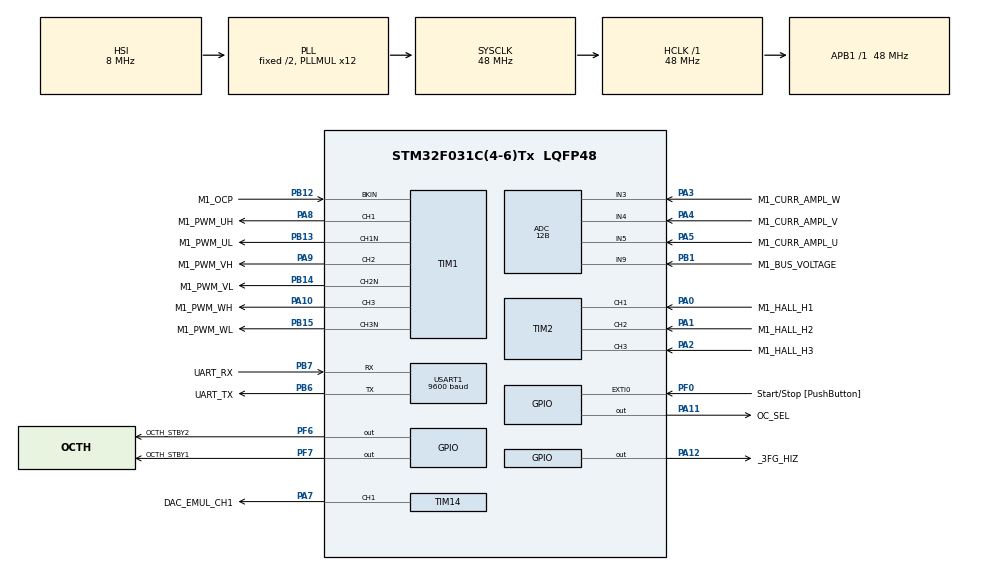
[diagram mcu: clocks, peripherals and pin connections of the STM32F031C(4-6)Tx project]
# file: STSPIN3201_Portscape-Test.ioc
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ADC.ClockPrescaler=ADC_CLOCK_ASYNC_DIV1
ADC.ContinuousConvMode=DISABLE
ADC.DMAContinuousRequests=ENABLE
ADC.DataAlign=ADC_DATAALIGN_LEFT
ADC.DiscontinuousConvMode=DISABLE
ADC.EOCSelection=ADC_EOC_SINGLE_CONV
ADC.EnableAnalogWatchDog=false
ADC.ExternalTrigConv=ADC_EXTERNALTRIGCONV_T1_TRGO
ADC.ExternalTrigConvEdge=ADC_EXTERNALTRIGCONVEDGE_RISING
ADC.LowPowerAutoPowerOff=DISABLE
ADC.LowPowerAutoWait=DISABLE
ADC.Overrun=ADC_OVR_DATA_PRESERVED
ADC.Resolution=ADC_RESOLUTION_12B
ADC.SamplingTime=ADC_SAMPLETIME_28CYCLES_5
ADC.ScanConvMode=ADC_SCAN_DIRECTION_FORWARD
Dma.ADC.0.Direction=DMA_PERIPH_TO_MEMORY
Dma.ADC.0.Instance=DMA1_Channel1
Dma.ADC.0.MemDataAlignment=DMA_MDATAALIGN_HALFWORD
Dma.ADC.0.MemInc=DMA_MINC_ENABLE
Dma.ADC.0.Mode=DMA_CIRCULAR
Dma.ADC.0.PeriphDataAlignment=DMA_PDATAALIGN_HALFWORD
Dma.ADC.0.PeriphInc=DMA_PINC_DISABLE
Dma.ADC.0.Priority=DMA_PRIORITY_HIGH
Dma.Request0=ADC
ExtraMW=MotorControl
ExtraMW.MotorControl.Config=MotorControl
ExtraMW.MotorControl.Mode=MotorControl
ExtraMW.MotorControl.Root=MCSDK_v5.4.8/MotorControl
ExtraMW.MotorControl.Template=templates
Mcu.Family=STM32F0
Mcu.Name=STM32F031C(4-6)Tx
Mcu.Package=LQFP48
MotorControl.ADC_1_PERIPH=ADC1
MotorControl.ADC_2_PERIPH=ADC2
MotorControl.ADC_AHBPERIPH=RCC_AHBPeriph_ADC12
MotorControl.ADC_CLOCK_WB_DIV=1
MotorControl.ADC_CLOCK_WB_FREQ=12
MotorControl.ADC_PERIPH=ADC1
MotorControl.ADC_REFERENCE_VOLTAGE=3.30
MotorControl.ALIGNMENT_ANGLE_DEG=90
MotorControl.ALIGNMENT_DURATION=700
MotorControl.AMPLIFICATION_GAIN=7.70
MotorControl.ANGC={0,0,0,0,0,0,0,0}
MotorControl.BEMF_CONSISTENCY_GAIN=64
MotorControl.BEMF_CONSISTENCY_TOL=64
MotorControl.BKIN1_FILTER=0
MotorControl.BKIN2_FILTER=0
MotorControl.BKIN2_MODE=NONE
MotorControl.BKIN_MODE=EXT_MODE
MotorControl.BOARD=STEVAL-SPIN3201
MotorControl.BRKIN2_GPIO_AF=GPIO_AF_2
MotorControl.BRKIN_GPIO_AF=GPIO_AF_2
MotorControl.BUS_VOLTAGE_READING=true
MotorControl.CCMRAM_ENABLED=false
MotorControl.CLOCK_FREQUENCY=CPU_CLK_48_MHZ
MotorControl.CLOCK_SOURCE=INTERNAL
MotorControl.CONSTANT1_D=23099
MotorControl.CONSTANT1_Q=23099
MotorControl.CONSTANT2_QD=5253
MotorControl.CORD_BEMF_CONSISTENCY_GAIN=64
MotorControl.CORD_BEMF_CONSISTENCY_TOL=64
MotorControl.CORD_F1=8192
MotorControl.CORD_F2=16384
MotorControl.CORD_FIFO_DEPTH_01HZ=64
MotorControl.CORD_FIFO_DEPTH_DPP=64
MotorControl.CORD_GAIN1=-8949
MotorControl.CORD_GAIN2=6439
MotorControl.CORD_MAX_ACCEL_DPPP=44
MotorControl.CORD_MEAS_ERRORS_BEFORE_FAULTS=3
MotorControl.CORD_VARIANCE_THRESHOLD=4
MotorControl.CPU_CLK_48_MHZ=true
MotorControl.CTRBDID=10010
MotorControl.CUBE_MX_VER=6.6.0
MotorControl.CURRENT_READING_TOPOLOGY=THREE_SHUNT
MotorControl.CURR_SAMPLING_TIME=28
MotorControl.DAC_EMULATED=true
MotorControl.DAC_EMULATED_1=CH1
MotorControl.DAC_FUNCTIONALITY=true
MotorControl.DAC_TIMER_CH1_GPIO_PIN=LL_GPIO_PIN_7
MotorControl.DAC_TIMER_CH1_GPIO_PORT=GPIOA
MotorControl.DAC_TIMER_CH2_GPIO_PIN=LL_GPIO_PIN_0
MotorControl.DAC_TIMER_CH2_GPIO_PORT=GPIOA
MotorControl.DAC_TIMER_SELECTION=TIM14
MotorControl.DC_CURRENT_RS_MEAS=4.37
MotorControl.DEBUG_DAC_CH1=true
MotorControl.DEBUG_DAC_CH2=false
MotorControl.DEFAULT_CONTROL_MODE=STC_SPEED_MODE
MotorControl.DEFAULT_DAC_CHANNEL_1=MC_PROTOCOL_REG_I_A
MotorControl.DEFAULT_DAC_CHANNEL_2=MC_PROTOCOL_REG_I_B
MotorControl.DEFAULT_DAC_MOTOR=0
MotorControl.DEFAULT_FLUX_COMPONENT=0
MotorControl.DEFAULT_TARGET_SPEED_RPM=4500
MotorControl.DEFAULT_TORQUE_COMPONENT=0
MotorControl.DISSIPATIVE_BRAKE_POLARITY=DOUT_ACTIVE_HIGH
MotorControl.DRIVES_NUMBER_SELECTION=SINGLEDRIVE
MotorControl.EMERGENCY2_STOP_GPIO_PIN=LL_GPIO_PIN_12
MotorControl.EMERGENCY2_STOP_GPIO_PORT=GPIOB
MotorControl.EMERGENCY_STOP_GPIO_PIN=LL_GPIO_PIN_12
MotorControl.EMERGENCY_STOP_GPIO_PORT=GPIOB
MotorControl.ENABLE_SL_ALGO_FROM_PHASE=3
MotorControl.ENCODER_AVAILABLE=false
MotorControl.ENCODER_PPR=400
MotorControl.ENC_AVERAGING_FIFO_DEPTH=16
MotorControl.ENC_A_GPIO_PIN=LL_GPIO_PIN_0
MotorControl.ENC_A_GPIO_PORT=GPIOA
MotorControl.ENC_B_GPIO_PIN=LL_GPIO_PIN_1
MotorControl.ENC_B_GPIO_PORT=GPIOA
MotorControl.ENC_ICx_FILTER=32
MotorControl.ENC_INVERT_SPEED=false
MotorControl.ENC_MEAS_ERRORS_BEFORE_FAULTS=3
MotorControl.ENC_TIMER_REMAPPING=NO_REMAP_TIM2
MotorControl.ENC_TIMER_SELECTION=ENC_TIM2
MotorControl.ENC_USE_CH3=false
MotorControl.EXT_CLOCK_FREQUENCY=INT_RC_OSC
MotorControl.F1=8192
MotorControl.F2=16384
MotorControl.FEEDBACK_NET_FILTERING=false
MotorControl.FEED_FORWARD_CURRENT_REG_ENABLING=false
MotorControl.FINAL_I_ALIGNMENT=2981
MotorControl.FLUX_WEAKENING_ENABLING=false
MotorControl.FW_KIDIV=32768
MotorControl.FW_KI_GAIN=5000
MotorControl.FW_KPDIV=32768
MotorControl.FW_KP_GAIN=3000
MotorControl.FW_VOLTAGE_REF=985
MotorControl.GAIN1=-8949
MotorControl.GAIN2=6439
MotorControl.H1_GPIO_PIN=LL_GPIO_PIN_0
MotorControl.H1_GPIO_PORT=GPIOA
MotorControl.H2_GPIO_PIN=LL_GPIO_PIN_1
MotorControl.H2_GPIO_PORT=GPIOA
MotorControl.H3_GPIO_PIN=LL_GPIO_PIN_2
MotorControl.H3_GPIO_PORT=GPIOA
MotorControl.HALL_AVERAGING_FIFO_DEPTH=6
MotorControl.HALL_ICx_FILTER=64
MotorControl.HALL_MEAS_ERRORS_BEFORE_FAULTS=3
MotorControl.HALL_MTPA=false
MotorControl.HALL_PHASE_SHIFT=300
MotorControl.HALL_SENSORS=true
MotorControl.HALL_SENSORS_AVAILABLE=true
MotorControl.HALL_SENSORS_PLACEMENT=DEGREES_120
MotorControl.HALL_TIMER_REMAPPING=NO_REMAP_TIM2
MotorControl.HALL_TIMER_SELECTION=HALL_TIM2
MotorControl.HFI_AMPLITUDE=25
MotorControl.HFI_DC_0_COEFF=0.00146
MotorControl.HFI_DC_1_COEFF=0.002921
MotorControl.HFI_DC_2_COEFF=0.00146
MotorControl.HFI_DC_3_COEFF=1.889033
MotorControl.HFI_DC_4_COEFF=-0.894874
MotorControl.HFI_DEBUG_MODE=false
MotorControl.HFI_FREQUENCY=400
MotorControl.HFI_HIFRAMPLSCAN=25
MotorControl.HFI_HP_ID_0_COEFF=0.910377
MotorControl.HFI_HP_ID_1_COEFF=-1.820754
MotorControl.HFI_HP_ID_2_COEFF=0.910377
MotorControl.HFI_HP_ID_3_COEFF=1.812706
MotorControl.HFI_HP_ID_4_COEFF=-0.828803
MotorControl.HFI_IDH_DELAY=32400
MotorControl.HFI_LOCKFREQ=49
MotorControl.HFI_LP_ID_0_COEFF=0.012898
MotorControl.HFI_LP_ID_1_COEFF=0.025796
MotorControl.HFI_LP_ID_2_COEFF=0.012898
MotorControl.HFI_LP_ID_3_COEFF=1.654019
MotorControl.HFI_LP_ID_4_COEFF=-0.705611
MotorControl.HFI_MAXANGLEDIFF=3640
MotorControl.HFI_MINIMUM_SPEED_RPM=402
MotorControl.HFI_NOTCH_IQD_0_COEFF=0.954985
MotorControl.HFI_NOTCH_IQD_1_COEFF=-1.875714
MotorControl.HFI_NOTCH_IQD_2_COEFF=0.954985
MotorControl.HFI_NOTCH_IQD_3_COEFF=1.875714
MotorControl.HFI_NOTCH_IQD_4_COEFF=-0.909971
MotorControl.HFI_NSDETPOINTSSKIP=10
MotorControl.HFI_NSMAXDETPOINTS=20
MotorControl.HFI_NS_MIN_SAT_DIFF=0
MotorControl.HFI_PID_KIDIV=32768
MotorControl.HFI_PID_KI_DEFAULT=400
MotorControl.HFI_PID_KPDIV=16384
MotorControl.HFI_PID_KP_DEFAULT=800
MotorControl.HFI_PLL_KI_DEFAULT=0.00400
MotorControl.HFI_PLL_KP_DEFAULT=0.00060
MotorControl.HFI_RESTARTTIMESEC=0.1
MotorControl.HFI_RESTART_RPM_TH=(((HFI_STO_RPM_TH)+(STO_HFI_RPM_TH))/2)
MotorControl.HFI_REVERT_DIRECTION=true
MotorControl.HFI_SCANROTATIONSNO=3
MotorControl.HFI_SPD_BUFFER_DEPTH_01HZ=64
MotorControl.HFI_STEPANGLE=3640
MotorControl.HFI_STO_RPM_TH=OBS_MINIMUM_SPEED_RPM
MotorControl.HFI_WAITAFTERNS2=4
MotorControl.HFI_WAITBEFORESN=6
MotorControl.HFI_WAITSYNCH=20
MotorControl.HFI_WAITTRACK=20
MotorControl.HIGH_SIDE_BRAKE_STATE=false
MotorControl.HIGH_SIDE_IDLE_STATE=false
MotorControl.HW_COMPLEMENTED_LOW_SIDE=false
MotorControl.HW_DEAD_TIME_NS=100
MotorControl.HW_OV_CURRENT_PROT_BYPASS=false
MotorControl.ID_DEMAG=-6682
MotorControl.INRUSH_CURRLIMIT_AT_POWER_ON=true
MotorControl.INRUSH_CURRLIMIT_CHANGE_AFTER_MS=1000
MotorControl.INRUSH_CURRLIMIT_ENABLING=false
MotorControl.INRUSH_CURRLIMIT_GPIO_PIN=LL_GPIO_PIN_4
MotorControl.INRUSH_CURRLIMIT_GPIO_PORT=GPIOE
MotorControl.INRUSH_CURR_LIMITER_POLARITY=DOUT_ACTIVE_HIGH
MotorControl.INTERNAL_OVERCURRENTPROTECTION=false
MotorControl.INTERNAL_OVERVOLTAGEPROTECTION=false
MotorControl.INT_RC_OSC=true
MotorControl.IPs=NVIC,RCC,SYS,MotorControl,TIM1,ADC,DMA,TIM2,TIM14,USART1
MotorControl.IQMAX=6682
MotorControl.LCD_JOYSTICK_FUNCTIONALITY=false
MotorControl.LCD_MODE=LCD_FULL
MotorControl.LDLQ_RATIO=1.000
MotorControl.LOW_SIDE_BRAKE_STATE=false
MotorControl.LOW_SIDE_IDLE_STATE=false
MotorControl.LOW_SIDE_SIGNALS_ENABLING=LS_PWM_TIMER
MotorControl.LS=0.000050
MotorControl.MAX_APPLICATION_SPEED=49000
MotorControl.MAX_MODULATION_81_PER_CENT=true
MotorControl.MAX_MODULATION_INDEX=MAX_MODULATION_81_PER_CENT
MotorControl.MCU=STSPIN32F0
MotorControl.MCU_TYPE=STSPIN32F0
MotorControl.MC_WORKBENCH_VERSION=5.4.8.21553
MotorControl.MEAS_ERRORS_BEFORE_FAULTS=3
MotorControl.MIN_APPLICATION_SPEED=0
MotorControl.MOTOR_MAX_SPEED_RPM=49000
MotorControl.MOTOR_TYPE=PMSM
MotorControl.MOTOR_VOLTAGE_CONSTANT=0.5
MotorControl.MTPA_ENABLING=false
MotorControl.NB_CONSECUTIVE_TESTS=2
MotorControl.NOMINAL_BUS_VOLTAGE_V=24
MotorControl.NOMINAL_CURRENT=6682
MotorControl.OBS_MEAS_ERRORS_BEFORE_FAULTS=3
MotorControl.OBS_MINIMUM_SPEED_RPM=580
MotorControl.OCPA_INVERTINGINPUT=COMPX_InvertingInput_VREF
MotorControl.OCPA_INVERTINGINPUT_GPIO_PIN=LL_GPIO_PIN_4
MotorControl.OCPA_INVERTINGINPUT_GPIO_PORT=GPIOA
MotorControl.OCPA_INVERTINGINPUT_MODE=INT_MODE
MotorControl.OCPA_NONINVERTINGINPUT=COMP1_NonInvertingInput_PA1
MotorControl.OCPA_NONINVERTINGINPUT_GPIO_PIN=LL_GPIO_PIN_1
MotorControl.OCPA_NONINVERTINGINPUT_GPIO_PORT=GPIOA
MotorControl.OCPA_OUTPUT=COMP_Output_TIM1BKIN2
MotorControl.OCPA_OUTPUTPOL=COMP_OutputPol_NonInverted
MotorControl.OCPA_OUTPUT_GPIO_AF=GPIO_AF_2
MotorControl.OCPA_OUTPUT_GPIO_PIN=LL_GPIO_PIN_0
MotorControl.OCPA_OUTPUT_GPIO_PORT=GPIOA
MotorControl.OCPA_OUTPUT_MODE=INT_MODE
MotorControl.OCPA_SELECTION=COMP1
MotorControl.OCPB_INVERTINGINPUT=COMPX_InvertingInput_VREF
MotorControl.OCPB_INVERTINGINPUT_GPIO_PIN=LL_GPIO_PIN_4
MotorControl.OCPB_INVERTINGINPUT_GPIO_PORT=GPIOA
MotorControl.OCPB_INVERTINGINPUT_MODE=INT_MODE
MotorControl.OCPB_NONINVERTINGINPUT=COMP2_NonInvertingInput_PA7
MotorControl.OCPB_NONINVERTINGINPUT_GPIO_PIN=LL_GPIO_PIN_7
MotorControl.OCPB_NONINVERTINGINPUT_GPIO_PORT=GPIOA
MotorControl.OCPB_OUTPUT=COMP_Output_TIM1BKIN2
MotorControl.OCPB_OUTPUTPOL=COMP_OutputPol_NonInverted
MotorControl.OCPB_OUTPUT_GPIO_AF=GPIO_AF_2
MotorControl.OCPB_OUTPUT_GPIO_PIN=LL_GPIO_PIN_2
MotorControl.OCPB_OUTPUT_GPIO_PORT=GPIOA
MotorControl.OCPB_OUTPUT_MODE=INT_MODE
MotorControl.OCPB_SELECTION=COMP2
MotorControl.OCPC_INVERTINGINPUT=COMPX_InvertingInput_VREF
MotorControl.OCPC_INVERTINGINPUT_GPIO_PIN=LL_GPIO_PIN_4
MotorControl.OCPC_INVERTINGINPUT_GPIO_PORT=GPIOA
MotorControl.OCPC_INVERTINGINPUT_MODE=INT_MODE
MotorControl.OCPC_NONINVERTINGINPUT=COMP3_NonInvertingInput_PB14
MotorControl.OCPC_NONINVERTINGINPUT_GPIO_PIN=LL_GPIO_PIN_14
MotorControl.OCPC_NONINVERTINGINPUT_GPIO_PORT=GPIOB
MotorControl.OCPC_OUTPUT=COMP_Output_TIM1BKIN2
MotorControl.OCPC_OUTPUTPOL=COMP_OutputPol_NonInverted
MotorControl.OCPC_OUTPUT_GPIO_AF=GPIO_AF_2
MotorControl.OCPC_OUTPUT_GPIO_PIN=LL_GPIO_PIN_8
MotorControl.OCPC_OUTPUT_GPIO_PORT=GPIOC
MotorControl.OCPC_OUTPUT_MODE=INT_MODE
MotorControl.OCPC_SELECTION=COMP3
MotorControl.OCPREF=23830
MotorControl.OCP_COMP_THRESHOLD=0.50
MotorControl.OCP_FILTER=COMP_Mode_HighSpeed
MotorControl.OCP_INVERTINGINPUT=COMPX_InvertingInput_VREF
MotorControl.OCP_INVERTINGINPUT_GPIO_PIN=LL_GPIO_PIN_4
MotorControl.OCP_INVERTINGINPUT_GPIO_PORT=GPIOA
MotorControl.OCP_INVERTINGINPUT_MODE=INT_MODE
MotorControl.OCP_NONINVERTINGINPUT=COMP2_NonInvertingInput_PA7
MotorControl.OCP_NONINVERTINGINPUT_GPIO_PIN=LL_GPIO_PIN_7
MotorControl.OCP_NONINVERTINGINPUT_GPIO_PORT=GPIOA
MotorControl.OCP_OUTPUT=COMP_Output_TIM1BKIN2
MotorControl.OCP_OUTPUTPOL=COMP_OutputPol_NonInverted
MotorControl.OCP_OUTPUT_GPIO_AF=GPIO_AF_2
MotorControl.OCP_OUTPUT_GPIO_PIN=LL_GPIO_PIN_2
MotorControl.OCP_OUTPUT_GPIO_PORT=GPIOA
MotorControl.OCP_OUTPUT_MODE=INT_MODE
MotorControl.OCP_SELECTION=COMP2
MotorControl.OFST={0,0,0,0,0,0,0,0}
MotorControl.ON_OVER_VOLTAGE=TURN_OFF_PWM
MotorControl.OPAMP1_INVERTINGINPUT=OPAMP1_InvertingInput_PGA
MotorControl.OPAMP1_INVERTINGINPUT_GPIO_PIN=LL_GPIO_PIN_3
MotorControl.OPAMP1_INVERTINGINPUT_GPIO_PORT=GPIOA
MotorControl.OPAMP1_INVERTINGINPUT_MODE=INT_MODE
MotorControl.OPAMP1_NONINVERTINGINPUT_PHA=OPAMP1_NonInvertingInput_PA1
MotorControl.OPAMP1_NONINVERTINGINPUT_PHA_GPIO_PIN=LL_GPIO_PIN_1
MotorControl.OPAMP1_NONINVERTINGINPUT_PHA_GPIO_PORT=GPIOA
MotorControl.OPAMP1_NONINVERTINGINPUT_PHB=OPAMP1_NonInvertingInput_PA7
MotorControl.OPAMP1_NONINVERTINGINPUT_PHB_GPIO_PIN=LL_GPIO_PIN_7
MotorControl.OPAMP1_NONINVERTINGINPUT_PHB_GPIO_PORT=GPIOA
MotorControl.OPAMP1_OUT_GPIO_PIN=LL_GPIO_PIN_2
MotorControl.OPAMP1_OUT_GPIO_PORT=GPIOA
MotorControl.OPAMP1_SELECTION=OPAMP1
MotorControl.OPAMP2_INVERTINGINPUT=OPAMP2_InvertingInput_PGA
MotorControl.OPAMP2_INVERTINGINPUT_GPIO_PIN=LL_GPIO_PIN_5
MotorControl.OPAMP2_INVERTINGINPUT_GPIO_PORT=GPIOC
MotorControl.OPAMP2_INVERTINGINPUT_MODE=INT_MODE
MotorControl.OPAMP2_NONINVERTINGINPUT_PHA=OPAMP2_NonInvertingInput_PB14
MotorControl.OPAMP2_NONINVERTINGINPUT_PHA_GPIO_PIN=LL_GPIO_PIN_14
MotorControl.OPAMP2_NONINVERTINGINPUT_PHA_GPIO_PORT=GPIOB
MotorControl.OPAMP2_NONINVERTINGINPUT_PHB=OPAMP2_NonInvertingInput_PA7
MotorControl.OPAMP2_NONINVERTINGINPUT_PHB_GPIO_PIN=LL_GPIO_PIN_7
MotorControl.OPAMP2_NONINVERTINGINPUT_PHB_GPIO_PORT=GPIOA
MotorControl.OPAMP2_NONINVERTINGINPUT_PHC=OPAMP2_NonInvertingInput_PB14
MotorControl.OPAMP2_NONINVERTINGINPUT_PHC_GPIO_PIN=LL_GPIO_PIN_14
MotorControl.OPAMP2_NONINVERTINGINPUT_PHC_GPIO_PORT=GPIOB
MotorControl.OPAMP2_OUT_GPIO_PIN=LL_GPIO_PIN_6
MotorControl.OPAMP2_OUT_GPIO_PORT=GPIOA
MotorControl.OPAMP2_SELECTION=OPAMP2
MotorControl.OPAMP3_INVERTINGINPUT=OPAMP1_InvertingInput_PGA
MotorControl.OPAMP3_INVERTINGINPUT_GPIO_PIN=LL_GPIO_PIN_0
MotorControl.OPAMP3_INVERTINGINPUT_GPIO_PORT=GPIOA
MotorControl.OPAMP3_INVERTINGINPUT_MODE=INT_MODE
MotorControl.OPAMP3_SELECTION=OPAMP1
MotorControl.OPAMP_INVERTINGINPUT=OPAMP1_InvertingInput_PGA
MotorControl.OPAMP_INVERTINGINPUT_GPIO_PIN=LL_GPIO_PIN_3
MotorControl.OPAMP_INVERTINGINPUT_GPIO_PORT=GPIOA
MotorControl.OPAMP_INVERTINGINPUT_MODE=INT_MODE
MotorControl.OPAMP_NONINVERTINGINPUT=OPAMP1_NonInvertingInput_PA7
MotorControl.OPAMP_NONINVERTINGINPUT_GPIO_PIN=LL_GPIO_PIN_7
MotorControl.OPAMP_NONINVERTINGINPUT_GPIO_PORT=GPIOA
MotorControl.OPAMP_OUT_GPIO_PIN=LL_GPIO_PIN_2
MotorControl.OPAMP_OUT_GPIO_PORT=GPIOA
MotorControl.OPAMP_PGACONNECT=OPAMP_PGAConnect_No
MotorControl.OPAMP_PGAGAIN=OPAMP_OPAMP_PGAGain_2
MotorControl.OPAMP_SELECTION=OPAMP1
MotorControl.OPAMP_TYPE_GAIN=INTERNAL
MotorControl.OPEN_LOOP_FOC=false
MotorControl.OPEN_LOOP_K=44
MotorControl.OPEN_LOOP_OFF=4400
MotorControl.OPEN_LOOP_SPEED_RAMP_DURATION_MS=1000
MotorControl.OPEN_LOOP_SPEED_RPM=100
MotorControl.OPEN_LOOP_VF=false
MotorControl.OPEN_LOOP_VOLTAGE_d=6000
MotorControl.OVERCURR_FEEDBACK_POLARITY=EMSTOP_ACTIVE_HIGH
MotorControl.OVERCURR_PROTECTION_HW_DISABLING=DOUT_ACTIVE_HIGH
MotorControl.OVPREF=23830
MotorControl.OVP_FILTER=COMP_Mode_HighSpeed
MotorControl.OVP_INVERTINGINPUT=COMPX_InvertingInput_VREF
MotorControl.OVP_INVERTINGINPUT_GPIO_PIN=LL_GPIO_PIN_4
MotorControl.OVP_INVERTINGINPUT_GPIO_PORT=GPIOA
MotorControl.OVP_INVERTINGINPUT_MODE=INT_MODE
MotorControl.OVP_NONINVERTINGINPUT=COMP7_NonInvertingInput_PA0
MotorControl.OVP_NONINVERTINGINPUT_GPIO_PIN=LL_GPIO_PIN_0
MotorControl.OVP_NONINVERTINGINPUT_GPIO_PORT=GPIOA
MotorControl.OVP_OUTPUT=COMP_Output_TIM1BKIN
MotorControl.OVP_OUTPUTPOL=COMP_OutputPol_NonInverted
MotorControl.OVP_OUTPUT_GPIO_AF=GPIO_AF_2
MotorControl.OVP_OUTPUT_GPIO_PIN=LL_GPIO_PIN_2
MotorControl.OVP_OUTPUT_GPIO_PORT=GPIOC
MotorControl.OVP_OUTPUT_MODE=INT_MODE
MotorControl.OVP_SELECTION=COMP7
MotorControl.OV_CURR_BYPASS_GPIO_PIN=LL_GPIO_PIN_5
MotorControl.OV_CURR_BYPASS_GPIO_PORT=GPIOE
MotorControl.OV_TEMPERATURE_HYSTERESIS_C=10
MotorControl.OV_TEMPERATURE_PROT_ENABLING=false
MotorControl.OV_TEMPERATURE_THRESHOLD_C=70
MotorControl.OV_VOLTAGE_PROT_ENABLING=true
MotorControl.OV_VOLTAGE_THRESHOLD_V=45
MotorControl.PHASE1_DURATION=0
MotorControl.PHASE1_FINAL_CURRENT=0
MotorControl.PHASE1_FINAL_SPEED_RPM=0
MotorControl.PHASE2_DURATION=700
MotorControl.PHASE2_FINAL_CURRENT=917
MotorControl.PHASE2_FINAL_SPEED_RPM=0
MotorControl.PHASE3_DURATION=350
MotorControl.PHASE3_FINAL_CURRENT=1070
MotorControl.PHASE3_FINAL_SPEED_RPM=630
MotorControl.PHASE4_DURATION=1150
MotorControl.PHASE4_FINAL_CURRENT=1070
MotorControl.PHASE4_FINAL_SPEED_RPM=2700
MotorControl.PHASE5_DURATION=0
MotorControl.PHASE5_FINAL_CURRENT=1070
MotorControl.PHASE5_FINAL_SPEED_RPM=2700
MotorControl.PHASE_CURRENTS_ADC=ADC1_2
MotorControl.PHASE_CURRENTS_CHANNEL=ADC_CHANNEL_9
MotorControl.PHASE_CURRENTS_GPIO_PIN=LL_GPIO_PIN_0
MotorControl.PHASE_CURRENTS_GPIO_PORT=GPIOA
MotorControl.PHASE_UH_GPIO_AF=GPIO_AF_2
MotorControl.PHASE_UH_GPIO_PIN=LL_GPIO_PIN_8
MotorControl.PHASE_UH_GPIO_PORT=GPIOA
MotorControl.PHASE_UH_POLARITY=H_ACTIVE_HIGH
MotorControl.PHASE_UL_GPIO_AF=GPIO_AF_2
MotorControl.PHASE_UL_GPIO_PIN=LL_GPIO_PIN_13
MotorControl.PHASE_UL_GPIO_PORT=GPIOB
MotorControl.PHASE_UL_POLARITY=L_ACTIVE_HIGH
MotorControl.PHASE_U_CURR_ADC=ADC1
MotorControl.PHASE_U_CURR_CHANNEL=ADC_CHANNEL_5
MotorControl.PHASE_U_GPIO_PIN=LL_GPIO_PIN_5
MotorControl.PHASE_U_GPIO_PORT=GPIOA
MotorControl.PHASE_VH_GPIO_AF=GPIO_AF_2
MotorControl.PHASE_VH_GPIO_PIN=LL_GPIO_PIN_9
MotorControl.PHASE_VH_GPIO_PORT=GPIOA
MotorControl.PHASE_VH_POLARITY=H_ACTIVE_HIGH
MotorControl.PHASE_VL_GPIO_AF=GPIO_AF_2
MotorControl.PHASE_VL_GPIO_PIN=LL_GPIO_PIN_14
MotorControl.PHASE_VL_GPIO_PORT=GPIOB
MotorControl.PHASE_VL_POLARITY=L_ACTIVE_HIGH
MotorControl.PHASE_V_CURR_ADC=ADC1
MotorControl.PHASE_V_CURR_CHANNEL=ADC_CHANNEL_4
MotorControl.PHASE_V_GPIO_PIN=LL_GPIO_PIN_4
MotorControl.PHASE_V_GPIO_PORT=GPIOA
MotorControl.PHASE_WH_GPIO_AF=GPIO_AF_2
MotorControl.PHASE_WH_GPIO_PIN=LL_GPIO_PIN_10
MotorControl.PHASE_WH_GPIO_PORT=GPIOA
MotorControl.PHASE_WH_POLARITY=H_ACTIVE_HIGH
MotorControl.PHASE_WL_GPIO_AF=GPIO_AF_2
MotorControl.PHASE_WL_GPIO_PIN=LL_GPIO_PIN_15
MotorControl.PHASE_WL_GPIO_PORT=GPIOB
MotorControl.PHASE_WL_POLARITY=L_ACTIVE_HIGH
MotorControl.PHASE_W_CURR_ADC=ADC1
MotorControl.PHASE_W_CURR_CHANNEL=ADC_CHANNEL_3
MotorControl.PHASE_W_GPIO_PIN=LL_GPIO_PIN_3
MotorControl.PHASE_W_GPIO_PORT=GPIOA
MotorControl.PID_FLUX_KD_DEFAULT=100
MotorControl.PID_FLUX_KI_DEFAULT=3577
MotorControl.PID_FLUX_KP_DEFAULT=3291
MotorControl.PID_SPEED_KD_DEFAULT=0
MotorControl.PID_SPEED_KI_DEFAULT=126
MotorControl.PID_SPEED_KP_DEFAULT=2044
MotorControl.PID_TORQUE_KD_DEFAULT=100
MotorControl.PID_TORQUE_KI_DEFAULT=3577
MotorControl.PID_TORQUE_KP_DEFAULT=3291
MotorControl.PLL_KI_GAIN=210
MotorControl.PLL_KP_GAIN=3935
MotorControl.POLE_PAIR_NUM=2
MotorControl.POSITION_CTRL_ENABLING=false
MotorControl.PWBDID=10010
MotorControl.PWM_FREQUENCY=26500
MotorControl.PWM_TIMER_REMAPPING=PWM_NO_REMAP
MotorControl.PWM_TIMER_SELECTION=PWM_TIM1
MotorControl.REGCONVADC=ADC1
MotorControl.REGULATION_EXECUTION_RATE=2
MotorControl.RS=0.36
MotorControl.RSHUNT=0.01000
MotorControl.RTOS=NONE
MotorControl.R_BRAKE_GPIO_PIN=LL_GPIO_PIN_5
MotorControl.R_BRAKE_GPIO_PORT=GPIOE
MotorControl.R_BRAKE_SWITCH_OFF_THRES_V=36
MotorControl.SEGDIV=0
MotorControl.SERIAL_COMMUNICATION=true
MotorControl.SERIAL_COM_CHANNEL1=MC_PROTOCOL_REG_I_A
MotorControl.SERIAL_COM_CHANNEL2=MC_PROTOCOL_REG_I_A
MotorControl.SERIAL_COM_MODE=COM_BIDIRECTIONAL
MotorControl.SERIAL_COM_MOTOR=0
MotorControl.SHARED_SIGNAL_ENABLE=false
MotorControl.SINGLEDRIVE=true
MotorControl.SPD_DIFFERENTIAL_TERM_ENABLING=false
MotorControl.SPEED_BAND_LOWER_LIMIT=15
MotorControl.SPEED_BAND_UPPER_LIMIT=17
MotorControl.SPEED_LOOP_FREQUENCY_HZ=1000
MotorControl.SPEED_SENSOR_SELECTION=HALL_SENSORS
MotorControl.SP_KDDIV=16
MotorControl.SP_KIDIV=16384
MotorControl.SP_KPDIV=1024
MotorControl.STARTING_ANGLE_DEG=90
MotorControl.START_STOP_BTN=true
MotorControl.START_STOP_GPIO_PIN=LL_GPIO_PIN_0
MotorControl.START_STOP_GPIO_PORT=GPIOF
MotorControl.START_STOP_POLARITY=DIN_ACTIVE_LOW
MotorControl.START_STOP_POLARITY_EDGE=GPIO_PULLUP
MotorControl.STO_FIFO_DEPTH_01HZ=64
MotorControl.STO_FIFO_DEPTH_DPP=64
MotorControl.STO_HFI_RPM_TH=460
MotorControl.STSPIN32F0=true
MotorControl.SW_DEADTIME_NS=800
MotorControl.SW_OV_CURRENT_PROT_ENABLING=true
MotorControl.T0_C=25
MotorControl.TEMPERATURE_READING=false
MotorControl.TEMP_ADC_SAMPLING_TIME=1
MotorControl.TEMP_FDBK_ADC=ADC1
MotorControl.TEMP_FDBK_CHANNEL=ADC_CHANNEL_5
MotorControl.TEMP_FDBK_GPIO_PIN=LL_GPIO_PIN_5
MotorControl.TEMP_FDBK_GPIO_PORT=GPIOA
MotorControl.TFDIFFERENTIAL_TERM_ENABLING=false
MotorControl.TF_KDDIV=8192
MotorControl.TF_KIDIV=8192
MotorControl.TF_KPDIV=4096
MotorControl.THREE_SHUNT=true
MotorControl.TNOISE_NS=1200
MotorControl.TRANSITION_DURATION=0
MotorControl.TRISE_NS=1200
MotorControl.T_MAX=70
MotorControl.UD_VOLTAGE_THRESHOLD_V=8
MotorControl.USART_REMAPPING=NO_REMAP_USART1
MotorControl.USART_RX_GPIO_PIN=LL_GPIO_PIN_7
MotorControl.USART_RX_GPIO_PORT=GPIOB
MotorControl.USART_SELECTION=USE_USART1
MotorControl.USART_SPEED=9600
MotorControl.USART_TX_GPIO_PIN=LL_GPIO_PIN_6
MotorControl.USART_TX_GPIO_PORT=GPIOB
MotorControl.USE_3OPAMPS=false
MotorControl.USE_INTERNAL_OPAMP=false
MotorControl.UV_VOLTAGE_PROT_ENABLING=true
MotorControl.V0_V=0.290
MotorControl.VARIANCE_THRESHOLD=0.1
MotorControl.VBUS_ADC=ADC1
MotorControl.VBUS_ADC_SAMPLING_TIME=28
MotorControl.VBUS_CHANNEL=ADC_CHANNEL_9
MotorControl.VBUS_GPIO_PIN=LL_GPIO_PIN_1
MotorControl.VBUS_GPIO_PORT=GPIOB
MotorControl.VBUS_PARTITIONING_FACTOR=0.0522
MotorControl.WB_to_Mx_template_version=21-11-15
MotorControl.WB_to_Mx_version=1.5.1
MotorControl.dV_dT=0.025
NVIC.DMA1_Channel1_IRQn=true\:1\:0\:true\:true\:false\:3\:true\:true\:true
NVIC.EXTI0_1_IRQn=true\:3\:0\:false\:true\:false\:6\:true\:true\:true
NVIC.TIM1_BRK_UP_TRG_COM_IRQn=true\:0\:0\:false\:true\:false\:1\:true\:true\:true
NVIC.TIM2_IRQn=true\:3\:0\:false\:true\:false\:4\:true\:true\:true
NVIC.USART1_IRQn=true\:3\:0\:true\:true\:false\:5\:true\:true\:true
PA0.GPIO_Label=M1_HALL_H1
PA0.GPIO_Speed=GPIO_SPEED_FREQ_HIGH
PA0.Signal=S_TIM2_CH1_ETR
PA1.GPIO_Label=M1_HALL_H2
PA1.GPIO_Speed=GPIO_SPEED_FREQ_HIGH
PA1.Signal=S_TIM2_CH2
PA10.GPIO_Label=M1_PWM_WH
PA10.GPIO_PuPd=GPIO_PULLDOWN
PA10.GPIO_Speed=GPIO_SPEED_FREQ_HIGH
PA10.Signal=S_TIM1_CH3
PA11.GPIO_Label=OC_SEL
PA11.GPIO_PuPd=GPIO_PULLDOWN
PA11.PinState=GPIO_PIN_SET
PA11.Signal=GPIO_Output
PA12.GPIO_Label=_3FG_HIZ
PA12.GPIO_PuPd=GPIO_PULLDOWN
PA12.Signal=GPIO_Output
PA2.GPIO_Label=M1_HALL_H3
PA2.GPIO_Speed=GPIO_SPEED_FREQ_HIGH
PA2.Signal=S_TIM2_CH3
PA3.GPIO_Label=M1_CURR_AMPL_W
PA3.Mode=IN3
PA3.Signal=ADC_IN3
PA4.GPIO_Label=M1_CURR_AMPL_V
PA4.Mode=IN4
PA4.Signal=ADC_IN4
PA5.GPIO_Label=M1_CURR_AMPL_U
PA5.Mode=IN5
PA5.Signal=ADC_IN5
PA7.GPIO_Label=DAC_EMUL_CH1
PA7.Signal=S_TIM14_CH1
PA8.GPIO_Label=M1_PWM_UH
PA8.GPIO_PuPd=GPIO_PULLDOWN
PA8.GPIO_Speed=GPIO_SPEED_FREQ_HIGH
PA8.Signal=S_TIM1_CH1
PA9.GPIO_Label=M1_PWM_VH
PA9.GPIO_PuPd=GPIO_PULLDOWN
PA9.GPIO_Speed=GPIO_SPEED_FREQ_HIGH
PA9.Signal=S_TIM1_CH2
PB1.GPIO_Label=M1_BUS_VOLTAGE
PB1.Mode=IN9
PB1.Signal=ADC_IN9
PB12.GPIO_Label=M1_OCP
PB12.GPIO_PuPd=GPIO_PULLDOWN
PB12.Mode=Activate-Break-Input
PB12.Signal=TIM1_BKIN
PB13.GPIO_Label=M1_PWM_UL
PB13.GPIO_PuPd=GPIO_PULLDOWN
PB13.GPIO_Speed=GPIO_SPEED_FREQ_HIGH
PB13.Mode=PWM Generation1 CH1 CH1N
PB13.Signal=TIM1_CH1N
PB14.GPIO_Label=M1_PWM_VL
PB14.GPIO_PuPd=GPIO_PULLDOWN
PB14.GPIO_Speed=GPIO_SPEED_FREQ_HIGH
PB14.Mode=PWM Generation2 CH2 CH2N
PB14.Signal=TIM1_CH2N
PB15.GPIO_Label=M1_PWM_WL
PB15.GPIO_PuPd=GPIO_PULLDOWN
PB15.GPIO_Speed=GPIO_SPEED_FREQ_HIGH
PB15.Mode=PWM Generation3 CH3 CH3N
PB15.Signal=TIM1_CH3N
PB6.GPIO_Label=UART_TX
PB6.GPIO_Mode=GPIO_MODE_AF_PP
PB6.GPIO_PuPd=GPIO_NOPULL
PB6.GPIO_Speed=GPIO_SPEED_FREQ_LOW
PB6.Mode=Asynchronous
PB6.Signal=USART1_TX
PB7.GPIO_Label=UART_RX
PB7.GPIO_Mode=GPIO_MODE_AF_PP
PB7.GPIO_PuPd=GPIO_NOPULL
PB7.GPIO_Speed=GPIO_SPEED_FREQ_LOW
PB7.Mode=Asynchronous
PB7.Signal=USART1_RX
PF0-OSC_IN.GPIO_Label=Start/Stop [PushButton]
PF0-OSC_IN.GPIO_ModeDefaultEXTI=GPIO_MODE_IT_FALLING
PF0-OSC_IN.GPIO_PuPd=GPIO_PULLUP
PF0-OSC_IN.Signal=GPXTI0
PF6.GPIO_Label=OCTH_STBY2
PF6.GPIO_PuPd=GPIO_PULLDOWN
PF6.PinState=GPIO_PIN_SET
PF6.Signal=GPIO_Output
PF7.GPIO_Label=OCTH_STBY1
PF7.GPIO_PuPd=GPIO_PULLDOWN
PF7.PinState=GPIO_PIN_SET
PF7.Signal=GPIO_Output
ProjectManager.HeapSize=0x80
ProjectManager.StackSize=0x400
ProjectManager.TargetToolchain=STM32CubeIDE
RCC.AHBFreq_Value=48000000
RCC.APB1Freq_Value=48000000
RCC.APB1TimFreq_Value=48000000
RCC.EnbaleCSS=true
RCC.HCLKFreq_Value=48000000
RCC.PLLMUL=RCC_PLL_MUL12
RCC.SYSCLKFreq_VALUE=48000000
RCC.SYSCLKSource=RCC_SYSCLKSOURCE_PLLCLK
SH.S_TIM14_CH1.0=TIM14_CH1,PWM Generation1 CH1
SH.S_TIM1_CH1.0=TIM1_CH1,PWM Generation1 CH1 CH1N
SH.S_TIM1_CH2.0=TIM1_CH2,PWM Generation2 CH2 CH2N
SH.S_TIM1_CH3.0=TIM1_CH3,PWM Generation3 CH3 CH3N
SH.S_TIM2_CH1_ETR.0=TIM2_CH1,Xored_Inputs_Hall_Sensor_Interface
SH.S_TIM2_CH2.0=TIM2_CH2,Xored_Inputs_Hall_Sensor_Interface
SH.S_TIM2_CH3.0=TIM2_CH3,Xored_Inputs_Hall_Sensor_Interface
TIM1.AutoReloadPreload=TIM_AUTORELOAD_PRELOAD_DISABLE
TIM1.AutomaticOutput=TIM_AUTOMATICOUTPUT_DISABLE
TIM1.BreakPolarity=TIM_BREAKPOLARITY_HIGH
TIM1.BreakState=TIM_BREAK_ENABLE
TIM1.Channel-PWM\ Generation1\ CH1\ CH1N=TIM_CHANNEL_1
TIM1.Channel-PWM\ Generation2\ CH2\ CH2N=TIM_CHANNEL_2
TIM1.Channel-PWM\ Generation3\ CH3\ CH3N=TIM_CHANNEL_3
TIM1.Channel-PWM\ Generation4\ No\ Output=TIM_CHANNEL_4
TIM1.ClockDivision=TIM_CLOCKDIVISION_DIV2
TIM1.CounterMode=TIM_COUNTERMODE_CENTERALIGNED1
TIM1.DeadTime=((DEAD_TIME_COUNTS) / 2)
TIM1.LockLevel=TIM_LOCKLEVEL_1
TIM1.OCIdleState_1=TIM_OCIDLESTATE_RESET
TIM1.OCIdleState_2=TIM_OCIDLESTATE_RESET
TIM1.OCIdleState_3=TIM_OCIDLESTATE_RESET
TIM1.OCIdleState_4=TIM_OCIDLESTATE_RESET
TIM1.OCMode_PWM-PWM\ Generation1\ CH1\ CH1N=TIM_OCMODE_PWM1
TIM1.OCMode_PWM-PWM\ Generation2\ CH2\ CH2N=TIM_OCMODE_PWM1
TIM1.OCMode_PWM-PWM\ Generation3\ CH3\ CH3N=TIM_OCMODE_PWM1
TIM1.OCMode_PWM-PWM\ Generation4\ No\ Output=TIM_OCMODE_PWM2
TIM1.OCNIdleState_1=TIM_OCNIDLESTATE_RESET
TIM1.OCNIdleState_2=TIM_OCNIDLESTATE_RESET
TIM1.OCNIdleState_3=TIM_OCNIDLESTATE_RESET
TIM1.OCNPolarity_1=TIM_OCNPOLARITY_HIGH
TIM1.OCNPolarity_2=TIM_OCNPOLARITY_HIGH
TIM1.OCNPolarity_3=TIM_OCNPOLARITY_HIGH
TIM1.OCPolarity_1=TIM_OCPOLARITY_HIGH
TIM1.OCPolarity_2=TIM_OCPOLARITY_HIGH
TIM1.OCPolarity_3=TIM_OCPOLARITY_HIGH
TIM1.OCPolarity_4=TIM_OCPOLARITY_HIGH
TIM1.OffStateIDLEMode=TIM_OSSI_ENABLE
TIM1.OffStateRunMode=TIM_OSSR_ENABLE
TIM1.Period=((PWM_PERIOD_CYCLES) / 2)
TIM1.Prescaler=((TIM_CLOCK_DIVIDER) - 1)
TIM1.Pulse-PWM\ Generation1\ CH1=((PWM_PERIOD_CYCLES) / 4)
TIM1.Pulse-PWM\ Generation2\ CH2=((PWM_PERIOD_CYCLES) / 4)
TIM1.Pulse-PWM\ Generation3\ CH3=((PWM_PERIOD_CYCLES) / 4)
TIM1.Pulse-PWM\ Generation4\ No\ Output=(((PWM_PERIOD_CYCLES) / 2) - (HTMIN))
TIM1.RepetitionCounter=(REP_COUNTER)
TIM1.TIM_MasterOutputTrigger=TIM_TRGO_OC4REF
TIM1.TIM_MasterSlaveMode=TIM_MASTERSLAVEMODE_DISABLE
TIM14.AutoReloadPreload=TIM_AUTORELOAD_PRELOAD_DISABLE
TIM14.Channel=TIM_CHANNEL_1
TIM14.ClockDivision=TIM_CLOCKDIVISION_DIV1
TIM14.CounterMode=TIM_COUNTERMODE_UP
TIM14.Period=0x800
TIM14.Prescaler=0
TIM14.Pulse=0x400
TIM2.IC1Filter=M1_HALL_IC_FILTER
TIM2.Period=M1_HALL_TIM_PERIOD
USART1.BaudRate=9600
USART1.VirtualMode-Asynchronous=VM_ASYNC
USART1.WordLength=WORDLENGTH_8B
VP_MotorControl_MC_ENABLED.Mode=Enabled
VP_TIM14_VS_ClockSourceINT.Mode=Enable_Timer
VP_TIM1_VS_no_output4.Mode=PWM Generation4 No Output
VP_TIM2_VS_ClockSourceINT.Mode=Internal
board=custom

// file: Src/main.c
/* USER CODE BEGIN Header */
/**
  ******************************************************************************
  * @file           : main.c
  * @brief          : Main program body
  ******************************************************************************
  * @attention
  *
  * Copyright (c) 2022 STMicroelectronics.
  * All rights reserved.
  *
  * This software is licensed under terms that can be found in the LICENSE file
  * in the root directory of this software component.
  * If no LICENSE file comes with this software, it is provided AS-IS.
  *
  ******************************************************************************
  */
/* USER CODE END Header */
#include "main.h"

ADC_HandleTypeDef hadc;
DMA_HandleTypeDef hdma_adc;

TIM_HandleTypeDef htim1;
TIM_HandleTypeDef htim2;
TIM_HandleTypeDef htim14;

UART_HandleTypeDef huart1;

void SystemClock_Config(void);
static void MX_GPIO_Init(void);
static void MX_DMA_Init(void);
static void MX_ADC_Init(void);
static void MX_TIM1_Init(void);
static void MX_TIM2_Init(void);
static void MX_TIM14_Init(void);
static void MX_USART1_UART_Init(void);
static void MX_NVIC_Init(void);
/*-- My code --*/
void Home_Offset(void);
void Mode_Home(void);
void Mode_Home2(void);
void Mode_Home3(void);
void Home_Null_Offset(void);

void OSC_MODE_HOME(void);
void OSC_MODE_HOME2(void);
void MainWhile_Homing(void);
/*-- My code ends --*/

/* USER CODE BEGIN 0 */
/*-- My code --*/
   bool stepA=1,stepB=0,stepC=0,stepCA=0,stepAB=0,stepBC=0,pendingPhase=1, moveMotor =1;
   uint16_t oldhallstate =0, presenthallstate=0,count =0,oldAngle=0,execute = 0,waitToMoveCounter =0;
   int16_t pulse = 100;
   uint8_t MotorHallState = 0;
   uint8_t buffer[20];
//   uint8_t homingOffset = 0;

   uint16_t Null_Offset = 0;
/*-- My code ends --*/
#define STATE_0 (uint8_t)0
#define STATE_1 (uint8_t)1
#define STATE_2 (uint8_t)2
#define STATE_3 (uint8_t)3
#define STATE_4 (uint8_t)4
#define STATE_5 (uint8_t)5
#define STATE_6 (uint8_t)6
#define STATE_7 (uint8_t)7
/* USER CODE END 0 */

int main(void)
{

  /* MCU Configuration--------------------------------------------------------*/

  /* Reset of all peripherals, Initializes the Flash interface and the Systick. */
  HAL_Init();

  /* Configure the system clock */
  SystemClock_Config();

  /* Initialize all configured peripherals */
  MX_GPIO_Init();
  MX_DMA_Init();
  MX_ADC_Init();
  MX_TIM1_Init();
  MX_TIM2_Init();
  MX_TIM14_Init();
  MX_USART1_UART_Init();
  MX_MotorControl_Init();

    /* Initialize interrupts */
    MX_NVIC_Init();
    /* USER CODE BEGIN 2 */

    __HAL_TIM_SET_COMPARE(&htim1,TIM_CHANNEL_1,0);
    __HAL_TIM_SET_COMPARE(&htim1,TIM_CHANNEL_2,0);
    __HAL_TIM_SET_COMPARE(&htim1,TIM_CHANNEL_3,0);
    HAL_TIM_PWM_Start(&htim1,TIM_CHANNEL_1);
    HAL_TIM_PWM_Start(&htim1,TIM_CHANNEL_2);
    HAL_TIM_PWM_Start(&htim1,TIM_CHANNEL_3);

    /* USER CODE END 2 */
    //MotorHallState = HALL_M1.HallStateCounter;
   // HAL_UART_Transmit(&huart1, (uint8_t*)buffer, sprintf(buffer, "\t STATE: %u\r\n", HALL_M1.HallStateCounter), 100);
    /* Infinite loop */
    /* USER CODE BEGIN WHILE */
    while (1)
    {
//    	HAL_UART_Transmit(&huart1, (uint8_t*)buffer, sprintf(buffer, "\t CASE 6, HallState:  %u\r\n", HALL_M1.HallState), 100);
//    	HAL_UART_Transmit(&huart1, (uint8_t*)buffer, sprintf(buffer, "\t CASE 6, HallStateCounter:  %u\r\n", HALL_M1.HallStateCounter), 100);
//    	HAL_UART_Transmit(&huart1, (uint8_t*)buffer, sprintf(buffer, "\t CASE 6, HallStateHomePosition:  %u\r\n", HALL_M1.HallStateHomePosition), 100);
//    	HAL_UART_Transmit(&huart1, (uint8_t*)buffer, sprintf(buffer, "\t CASE 6, HallCounterHomePosition:  %u\r\n", HALL_M1.HallCounterHomePosition), 100);
    	HAL_UART_Transmit(&huart1, (uint8_t*)buffer, sprintf(buffer, "\t CASE 6, HallCounterHomePosition:  %u\r\n", Null_Offset), 100);
    	HAL_Delay(1000);
    /* USER CODE BEGIN 3 */
  }
  /* USER CODE END 3 */
}

void Mode_Home(){

	uint8_t HallState_Internal = HALL_M1.HallState;
	uint8_t HallStateCounter_Internal = (HALL_M1.HallStateCounter + (Null_Offset%72));
	uint8_t HallState_Home = HALL_M1.HallStateHomePosition;
	uint8_t HallStateCounter_Home = HALL_M1.HallCounterHomePosition;

//	HAL_UART_Transmit(&huart1, (uint8_t*)buffer, sprintf(buffer, "\t Input:  %u\r\n", HallState_Internal), 100);
	while (HallStateCounter_Internal != HallStateCounter_Home){ //&&(HallState_Home != HallState_Home)
		switch(HallState_Internal){
		//step 1
				case STATE_6:
					  __HAL_TIM_SET_COMPARE(&htim1,TIM_CHANNEL_1,pulse);
					  __HAL_TIM_SET_COMPARE(&htim1,TIM_CHANNEL_2,0);
					  __HAL_TIM_SET_COMPARE(&htim1,TIM_CHANNEL_3,0);
					  HallState_Internal++;
					  HallStateCounter_Internal++;
					  HAL_UART_Transmit(&huart1, (uint8_t*)buffer, sprintf(buffer, "\t CASE 6, HallState:  %u\r\n", HallState_Internal), 100);
//					  HAL_UART_Transmit(&huart1, (uint8_t*)buffer, sprintf(buffer, "\t CASE 5, HallCounter:  %u\r\n", HallStateCounter_Internal), 100);
//					  HAL_UART_Transmit(&huart1, (uint8_t*)buffer, sprintf(buffer, "\t CASE 5, HallStateCounter_Home:  %u\r\n", HallStateCounter_Home), 100);
					break;
				//step 2
				case STATE_1:
				  	  __HAL_TIM_SET_COMPARE(&htim1,TIM_CHANNEL_1,pulse);
				  	  __HAL_TIM_SET_COMPARE(&htim1,TIM_CHANNEL_2,pulse);
				  	  __HAL_TIM_SET_COMPARE(&htim1,TIM_CHANNEL_3,0);
					  HallState_Internal++;
					  HallStateCounter_Internal++;
					  HAL_UART_Transmit(&huart1, (uint8_t*)buffer, sprintf(buffer, "\t CASE 1, HallState:  %u\r\n", HallState_Internal), 100);
//					  HAL_UART_Transmit(&huart1, (uint8_t*)buffer, sprintf(buffer, "\t CASE 3, HallCounter:  %u\r\n", HallStateCounter_Internal), 100);
//					  HAL_UART_Transmit(&huart1, (uint8_t*)buffer, sprintf(buffer, "\t CASE 5, HallStateCounter_Home:  %u\r\n", HallStateCounter_Home), 100);
					break;
				//step 3
				case STATE_2:
					  __HAL_TIM_SET_COMPARE(&htim1,TIM_CHANNEL_1,0);
					  __HAL_TIM_SET_COMPARE(&htim1,TIM_CHANNEL_2,pulse);
					  __HAL_TIM_SET_COMPARE(&htim1,TIM_CHANNEL_3,0);
					  HallState_Internal++;
					  HallStateCounter_Internal++;
					  HAL_UART_Transmit(&huart1, (uint8_t*)buffer, sprintf(buffer, "\t CASE 2, HallState:  %u\r\n", HallState_Internal), 100);
//					  HAL_UART_Transmit(&huart1, (uint8_t*)buffer, sprintf(buffer, "\t CASE 1, HallCounter:  %u\r\n", HallStateCounter_Internal), 100);
//					  HAL_UART_Transmit(&huart1, (uint8_t*)buffer, sprintf(buffer, "\t CASE 5, HallStateCounter_Home:  %u\r\n", HallStateCounter_Home), 100);
					break;
				//step 4
				case STATE_3:
				  	    __HAL_TIM_SET_COMPARE(&htim1,TIM_CHANNEL_1,0);
				  	    __HAL_TIM_SET_COMPARE(&htim1,TIM_CHANNEL_2,pulse);
				  	    __HAL_TIM_SET_COMPARE(&htim1,TIM_CHANNEL_3,pulse);
						  HallState_Internal++;
						  HallStateCounter_Internal++;
						  HAL_UART_Transmit(&huart1, (uint8_t*)buffer, sprintf(buffer, "\t CASE 3, HallState:  %u\r\n", HallState_Internal), 100);
//						  HAL_UART_Transmit(&huart1, (uint8_t*)buffer, sprintf(buffer, "\t CASE 6, HallCounter:  %u\r\n", HallStateCounter_Internal), 100);
//						  HAL_UART_Transmit(&huart1, (uint8_t*)buffer, sprintf(buffer, "\t CASE 5, HallStateCounter_Home:  %u\r\n", HallStateCounter_Home), 100);
					break;
				//step 5
				case STATE_4:
					__HAL_TIM_SET_COMPARE(&htim1,TIM_CHANNEL_1,0);
					__HAL_TIM_SET_COMPARE(&htim1,TIM_CHANNEL_2,0);
					__HAL_TIM_SET_COMPARE(&htim1,TIM_CHANNEL_3,pulse);
					  HallState_Internal++;
					  HallStateCounter_Internal++;
					  HAL_UART_Transmit(&huart1, (uint8_t*)buffer, sprintf(buffer, "\t CASE 4, HallState:  %u\r\n", HallState_Internal), 100);
//					  HAL_UART_Transmit(&huart1, (uint8_t*)buffer, sprintf(buffer, "\t CASE 4, HallCounter:  %u\r\n", HallStateCounter_Internal), 100);
//					  HAL_UART_Transmit(&huart1, (uint8_t*)buffer, sprintf(buffer, "\t CASE 5, HallStateCounter_Home:  %u\r\n", HallStateCounter_Home), 100);
					break;
				//step 6
				case STATE_5:
					 __HAL_TIM_SET_COMPARE(&htim1,TIM_CHANNEL_1,pulse);
					 __HAL_TIM_SET_COMPARE(&htim1,TIM_CHANNEL_2,0);
					 __HAL_TIM_SET_COMPARE(&htim1,TIM_CHANNEL_3,pulse);
					  HallState_Internal++;
					  HallStateCounter_Internal++;
					  HAL_UART_Transmit(&huart1, (uint8_t*)buffer, sprintf(buffer, "\t CASE 5, HallState:  %u\r\n", HallState_Internal), 100);
//					  HAL_UART_Transmit(&huart1, (uint8_t*)buffer, sprintf(buffer, "\t CASE 2, HallCounter:  %u\r\n", HallStateCounter_Internal), 100);
//					  HAL_UART_Transmit(&huart1, (uint8_t*)buffer, sprintf(buffer, "\t CASE 5, HallStateCounter_Home:  %u\r\n", HallStateCounter_Home), 100);
					break;
				default:
					HAL_UART_Transmit(&huart1, (uint8_t*)buffer, sprintf(buffer, "\t Error, HallState:  %u\r\n", HallState_Internal), 100);
//					HAL_UART_Transmit(&huart1, (uint8_t*)buffer, sprintf(buffer, "\t Error, HallCounter:  %u\r\n", HallStateCounter_Internal), 100);
//					HAL_UART_Transmit(&huart1, (uint8_t*)buffer, sprintf(buffer, "\t CASE 5, HallStateCounter_Home:  %u\r\n", HallStateCounter_Home), 100);
					break;
		}

		HallStateCounter_Internal = HallStateCounter_Internal%72;

		if(HallState_Internal ==7)
		{
			HallState_Internal =1;
		}

	}
	  __HAL_TIM_SET_COMPARE(&htim1,TIM_CHANNEL_1,0);
	  __HAL_TIM_SET_COMPARE(&htim1,TIM_CHANNEL_2,0);
	  __HAL_TIM_SET_COMPARE(&htim1,TIM_CHANNEL_3,0);
	  //NOte this two lines
//	  HALL_M1.HallStateCounter = 0;
	  HALL_M1.HallStateCounter = HALL_M1.HallCounterHomePosition;
	  HALL_M1.HallStateHomePosition = HALL_M1.HallState;
	  Null_Offset = 0;
}

//void Home_Offset(){
//	HAL_UART_Transmit(&huart1, (uint8_t*)buffer, sprintf(buffer, "---------------------------------------\n"), 100);
//	HAL_UART_Transmit(&huart1, (uint8_t*)buffer, sprintf(buffer, "\t Prev STATE COunter: %u\r\n", HALL_M1.HallCounterHomePosition), 100);
//	HAL_UART_Transmit(&huart1, (uint8_t*)buffer, sprintf(buffer, "\t PRev Hall POSITION: %u\r\n", HALL_M1.HallStateHomePosition), 100);
//	HALL_M1.HallCounterHomePosition = HALL_M1.HallStateCounter +1;
////	homingOffset = HALL_M1.HallStateCounter +1;
////	homingOffset +=1;
////	homingOffset = homingOffset%72;
//	//HALL_M1.HallStateHomePosition = HALL_M1.HallState;
//	HAL_UART_Transmit(&huart1, (uint8_t*)buffer, sprintf(buffer, "\t New STATE COunter: %u\r\n", HALL_M1.HallCounterHomePosition), 100);
//	HAL_UART_Transmit(&huart1, (uint8_t*)buffer, sprintf(buffer, "\t New Hall POSITION: %u\r\n", HALL_M1.HallStateHomePosition), 100);
//	Mode_Home2();
////	HALL_M1.HallStateCounter = HALL_M1.HallCounterHomePosition;
//	HAL_UART_Transmit(&huart1, (uint8_t*)buffer, sprintf(buffer, "---------------------------------------\n"), 100);
//}

void Home_Offset(){
	// 21 01 10 34
//	HAL_UART_Transmit(&huart1, (uint8_t*)buffer, sprintf(buffer, "\t Prev HALL homrCOunter: %u\r\n", HALL_M1.HallCounterHomePosition), 100);
//	HAL_UART_Transmit(&huart1, (uint8_t*)buffer, sprintf(buffer, "\t PRev Hall State home POSITION: %u\r\n", HALL_M1.HallStateHomePosition), 100);
	HALL_M1.HallCounterHomePosition = HALL_M1.HallCounterHomePosition +1;
//	HALL_M1.HallStateHomePosition = HALL_M1.HallState;
//	HAL_UART_Transmit(&huart1, (uint8_t*)buffer, sprintf(buffer, "\t New HAll home COunter: %u\r\n", HALL_M1.HallCounterHomePosition), 100);
//	HAL_UART_Transmit(&huart1, (uint8_t*)buffer, sprintf(buffer, "\t New Hall home State POSITION: %u\r\n", HALL_M1.HallStateHomePosition), 100);
	Mode_Home3();
//	HAL_UART_Transmit(&huart1, (uint8_t*)buffer, sprintf(buffer, "\t Final HAll Home COunter: %u\r\n", HALL_M1.HallCounterHomePosition), 100);
//	HAL_UART_Transmit(&huart1, (uint8_t*)buffer, sprintf(buffer, "\t Final Hall state home POSITION: %u\r\n", HALL_M1.HallStateHomePosition), 100);
//	HAL_UART_Transmit(&huart1, (uint8_t*)buffer, sprintf(buffer, "\t Final hall COunter: %u\r\n", HALL_M1.HallStateCounter), 100);
//	HAL_UART_Transmit(&huart1, (uint8_t*)buffer, sprintf(buffer, "\t Final Hall POSITION: %u\r\n", HALL_M1.HallState), 100);
}
void Mode_Home3(){

	uint8_t HallState_Internal = HALL_M1.HallState;
	uint8_t HallStateCounter_Internal = HALL_M1.HallStateCounter;
	uint8_t HallState_Home = HALL_M1.HallStateHomePosition;
	uint8_t HallStateCounter_Home = HALL_M1.HallCounterHomePosition;

	HAL_UART_Transmit(&huart1, (uint8_t*)buffer, sprintf(buffer, "\t Input:  %u\r\n", HallState_Internal), 100);
//	while (HallStateCounter_Internal != HallStateCounter_Home){ //&&(HallState_Home != HallState_Home)
		switch(HallState_Internal){
		//step 1
				case STATE_6:
					  __HAL_TIM_SET_COMPARE(&htim1,TIM_CHANNEL_1,0);
					  __HAL_TIM_SET_COMPARE(&htim1,TIM_CHANNEL_2,pulse);
					  __HAL_TIM_SET_COMPARE(&htim1,TIM_CHANNEL_3,pulse);
					  HallState_Internal++;
					  HallStateCounter_Internal++;
					  HAL_UART_Transmit(&huart1, (uint8_t*)buffer, sprintf(buffer, "\t CASE 6, HallState:  %u\r\n", HallState_Internal), 100);
//					  HAL_UART_Transmit(&huart1, (uint8_t*)buffer, sprintf(buffer, "\t CASE 5, HallCounter:  %u\r\n", HallStateCounter_Internal), 100);
//					  HAL_UART_Transmit(&huart1, (uint8_t*)buffer, sprintf(buffer, "\t CASE 5, HallStateCounter_Home:  %u\r\n", HallStateCounter_Home), 100);
					break;
				//step 2
				case STATE_1:
				  	  __HAL_TIM_SET_COMPARE(&htim1,TIM_CHANNEL_1,0);
				  	  __HAL_TIM_SET_COMPARE(&htim1,TIM_CHANNEL_2,0);
				  	  __HAL_TIM_SET_COMPARE(&htim1,TIM_CHANNEL_3,pulse);
					  HallState_Internal++;
					  HallStateCounter_Internal++;
					  HAL_UART_Transmit(&huart1, (uint8_t*)buffer, sprintf(buffer, "\t CASE 1, HallState:  %u\r\n", HallState_Internal), 100);
//					  HAL_UART_Transmit(&huart1, (uint8_t*)buffer, sprintf(buffer, "\t CASE 3, HallCounter:  %u\r\n", HallStateCounter_Internal), 100);
//					  HAL_UART_Transmit(&huart1, (uint8_t*)buffer, sprintf(buffer, "\t CASE 5, HallStateCounter_Home:  %u\r\n", HallStateCounter_Home), 100);
					break;
				//step 3
				case STATE_2:
					  __HAL_TIM_SET_COMPARE(&htim1,TIM_CHANNEL_1,pulse);
					  __HAL_TIM_SET_COMPARE(&htim1,TIM_CHANNEL_2,0);
					  __HAL_TIM_SET_COMPARE(&htim1,TIM_CHANNEL_3,pulse);
					  HallState_Internal++;
					  HallStateCounter_Internal++;
					  HAL_UART_Transmit(&huart1, (uint8_t*)buffer, sprintf(buffer, "\t CASE 2, HallState:  %u\r\n", HallState_Internal), 100);
//					  HAL_UART_Transmit(&huart1, (uint8_t*)buffer, sprintf(buffer, "\t CASE 1, HallCounter:  %u\r\n", HallStateCounter_Internal), 100);
//					  HAL_UART_Transmit(&huart1, (uint8_t*)buffer, sprintf(buffer, "\t CASE 5, HallStateCounter_Home:  %u\r\n", HallStateCounter_Home), 100);
					break;
				//step 4
				case STATE_3:
				  	    __HAL_TIM_SET_COMPARE(&htim1,TIM_CHANNEL_1,pulse);
				  	    __HAL_TIM_SET_COMPARE(&htim1,TIM_CHANNEL_2,0);
				  	    __HAL_TIM_SET_COMPARE(&htim1,TIM_CHANNEL_3,0);
						  HallState_Internal++;
						  HallStateCounter_Internal++;
						  HAL_UART_Transmit(&huart1, (uint8_t*)buffer, sprintf(buffer, "\t CASE 3, HallState:  %u\r\n", HallState_Internal), 100);
//						  HAL_UART_Transmit(&huart1, (uint8_t*)buffer, sprintf(buffer, "\t CASE 6, HallCounter:  %u\r\n", HallStateCounter_Internal), 100);
//						  HAL_UART_Transmit(&huart1, (uint8_t*)buffer, sprintf(buffer, "\t CASE 5, HallStateCounter_Home:  %u\r\n", HallStateCounter_Home), 100);
					break;
				//step 5
				case STATE_4:
					__HAL_TIM_SET_COMPARE(&htim1,TIM_CHANNEL_1,pulse);
					__HAL_TIM_SET_COMPARE(&htim1,TIM_CHANNEL_2,pulse);
					__HAL_TIM_SET_COMPARE(&htim1,TIM_CHANNEL_3,0);
					  HallState_Internal++;
					  HallStateCounter_Internal++;
					  HAL_UART_Transmit(&huart1, (uint8_t*)buffer, sprintf(buffer, "\t CASE 4, HallState:  %u\r\n", HallState_Internal), 100);
//					  HAL_UART_Transmit(&huart1, (uint8_t*)buffer, sprintf(buffer, "\t CASE 4, HallCounter:  %u\r\n", HallStateCounter_Internal), 100);
//					  HAL_UART_Transmit(&huart1, (uint8_t*)buffer, sprintf(buffer, "\t CASE 5, HallStateCounter_Home:  %u\r\n", HallStateCounter_Home), 100);
					break;
				//step 6
				case STATE_5:
					 __HAL_TIM_SET_COMPARE(&htim1,TIM_CHANNEL_1,0);
					 __HAL_TIM_SET_COMPARE(&htim1,TIM_CHANNEL_2,pulse);
					 __HAL_TIM_SET_COMPARE(&htim1,TIM_CHANNEL_3,0);
					  HallState_Internal++;
					  HallStateCounter_Internal++;
					  HAL_UART_Transmit(&huart1, (uint8_t*)buffer, sprintf(buffer, "\t CASE 5, HallState:  %u\r\n", HallState_Internal), 100);
//					  HAL_UART_Transmit(&huart1, (uint8_t*)buffer, sprintf(buffer, "\t CASE 2, HallCounter:  %u\r\n", HallStateCounter_Internal), 100);
//					  HAL_UART_Transmit(&huart1, (uint8_t*)buffer, sprintf(buffer, "\t CASE 5, HallStateCounter_Home:  %u\r\n", HallStateCounter_Home), 100);
					break;
				default:
					HAL_UART_Transmit(&huart1, (uint8_t*)buffer, sprintf(buffer, "\t Error, HallState:  %u\r\n", HallState_Internal), 100);
//					HAL_UART_Transmit(&huart1, (uint8_t*)buffer, sprintf(buffer, "\t Error, HallCounter:  %u\r\n", HallStateCounter_Internal), 100);
//					HAL_UART_Transmit(&huart1, (uint8_t*)buffer, sprintf(buffer, "\t CASE 5, HallStateCounter_Home:  %u\r\n", HallStateCounter_Home), 100);
					break;
		}

		HallStateCounter_Internal = HallStateCounter_Internal%72;

		if(HallState_Internal ==7)
		{
			HallState_Internal =1;
		}

//	}
	  __HAL_TIM_SET_COMPARE(&htim1,TIM_CHANNEL_1,0);
	  __HAL_TIM_SET_COMPARE(&htim1,TIM_CHANNEL_2,0);
	  __HAL_TIM_SET_COMPARE(&htim1,TIM_CHANNEL_3,0);
	  //NOte this two lines
//	  HALL_M1.HallStateCounter = 0;
	  HALL_M1.HallStateCounter = HALL_M1.HallCounterHomePosition;
	  HALL_M1.HallStateHomePosition = HALL_M1.HallState;
}
void Mode_Home2(){
	uint8_t HallState_Internal = HALL_M1.HallState;
	uint8_t HallStateCounter_Internal = HALL_M1.HallStateCounter;
	uint8_t HallState_Home = HALL_M1.HallStateHomePosition;
	uint8_t HallStateCounter_Home = HALL_M1.HallCounterHomePosition;// + homingOffset;

	while (HallStateCounter_Internal != HallStateCounter_Home){ //&&(HallState_Home != HallState_Home)
		switch(HallState_Internal){
			   //step 1
			   case STATE_6://STATE_2:
					  __HAL_TIM_SET_COMPARE(&htim1,TIM_CHANNEL_1,0);
					  __HAL_TIM_SET_COMPARE(&htim1,TIM_CHANNEL_2,pulse);
					  __HAL_TIM_SET_COMPARE(&htim1,TIM_CHANNEL_3,0);
					  HallState_Internal++;
					  HallStateCounter_Internal++;
					  HAL_UART_Transmit(&huart1, (uint8_t*)buffer, sprintf(buffer, "\t CASE 6, HallState:  %u\r\n", HallState_Internal), 100);
//					  HAL_UART_Transmit(&huart1, (uint8_t*)buffer, sprintf(buffer, "\t CASE 5, HallCounter:  %u\r\n", HallStateCounter_Internal), 100);
//					  HAL_UART_Transmit(&huart1, (uint8_t*)buffer, sprintf(buffer, "\t CASE 5, HallStateCounter_Home:  %u\r\n", HallStateCounter_Home), 100);
//				      for(int i =0; i<5000;i++);
					break;
				//step 2
				case STATE_1://STATE_3:
				  	  __HAL_TIM_SET_COMPARE(&htim1,TIM_CHANNEL_1,pulse);
				  	  __HAL_TIM_SET_COMPARE(&htim1,TIM_CHANNEL_2,0);
				  	  __HAL_TIM_SET_COMPARE(&htim1,TIM_CHANNEL_3,0);
					  HallState_Internal++;
					  HallStateCounter_Internal++;
					  HAL_UART_Transmit(&huart1, (uint8_t*)buffer, sprintf(buffer, "\t CASE 1, HallState:  %u\r\n", HallState_Internal), 100);
//					  HAL_UART_Transmit(&huart1, (uint8_t*)buffer, sprintf(buffer, "\t CASE 3, HallCounter:  %u\r\n", HallStateCounter_Internal), 100);
//					  HAL_UART_Transmit(&huart1, (uint8_t*)buffer, sprintf(buffer, "\t CASE 5, HallStateCounter_Home:  %u\r\n", HallStateCounter_Home), 100);
//				      for(int i =0; i<5000;i++);
					break;
				//step 3
				case STATE_2://STATE_4:
					  __HAL_TIM_SET_COMPARE(&htim1,TIM_CHANNEL_1,pulse);
					  __HAL_TIM_SET_COMPARE(&htim1,TIM_CHANNEL_2,pulse);
					  __HAL_TIM_SET_COMPARE(&htim1,TIM_CHANNEL_3,0);
					  HallState_Internal++;
					  HallStateCounter_Internal++;
					  HAL_UART_Transmit(&huart1, (uint8_t*)buffer, sprintf(buffer, "\t CASE 2, HallState:  %u\r\n", HallState_Internal), 100);
//					  HAL_UART_Transmit(&huart1, (uint8_t*)buffer, sprintf(buffer, "\t CASE 1, HallCounter:  %u\r\n", HallStateCounter_Internal), 100);
//					  HAL_UART_Transmit(&huart1, (uint8_t*)buffer, sprintf(buffer, "\t CASE 5, HallStateCounter_Home:  %u\r\n", HallStateCounter_Home), 100);
//				      for(int i =0; i<5000;i++);
					break;
				//step 4
				case STATE_3://STATE_5:
				  	    __HAL_TIM_SET_COMPARE(&htim1,TIM_CHANNEL_1,0);
				  	    __HAL_TIM_SET_COMPARE(&htim1,TIM_CHANNEL_2,pulse);
				  	    __HAL_TIM_SET_COMPARE(&htim1,TIM_CHANNEL_3,pulse);
						  HallState_Internal++;
						  HallStateCounter_Internal++;
						  HAL_UART_Transmit(&huart1, (uint8_t*)buffer, sprintf(buffer, "\t CASE 3, HallState:  %u\r\n", HallState_Internal), 100);
//						  HAL_UART_Transmit(&huart1, (uint8_t*)buffer, sprintf(buffer, "\t CASE 6, HallCounter:  %u\r\n", HallStateCounter_Internal), 100);
//						  HAL_UART_Transmit(&huart1, (uint8_t*)buffer, sprintf(buffer, "\t CASE 5, HallStateCounter_Home:  %u\r\n", HallStateCounter_Home), 100);
//					      for(int i =0; i<5000;i++);
					break;
				//step 5
				case STATE_4://STATE_6:
					__HAL_TIM_SET_COMPARE(&htim1,TIM_CHANNEL_1,0);
					__HAL_TIM_SET_COMPARE(&htim1,TIM_CHANNEL_2,0);
					__HAL_TIM_SET_COMPARE(&htim1,TIM_CHANNEL_3,pulse);
					  HallState_Internal++;
					  HallStateCounter_Internal++;
					  HAL_UART_Transmit(&huart1, (uint8_t*)buffer, sprintf(buffer, "\t CASE 4, HallState:  %u\r\n", HallState_Internal), 100);
//					  HAL_UART_Transmit(&huart1, (uint8_t*)buffer, sprintf(buffer, "\t CASE 4, HallCounter:  %u\r\n", HallStateCounter_Internal), 100);
//					  HAL_UART_Transmit(&huart1, (uint8_t*)buffer, sprintf(buffer, "\t CASE 5, HallStateCounter_Home:  %u\r\n", HallStateCounter_Home), 100);
//				      for(int i =0; i<5000;i++);
					break;
				//step 6
				case STATE_5://STATE_1:
					 __HAL_TIM_SET_COMPARE(&htim1,TIM_CHANNEL_1,pulse);
					 __HAL_TIM_SET_COMPARE(&htim1,TIM_CHANNEL_2,0);
					 __HAL_TIM_SET_COMPARE(&htim1,TIM_CHANNEL_3,pulse);
					  HallState_Internal++;
					  HallStateCounter_Internal++;
					  HAL_UART_Transmit(&huart1, (uint8_t*)buffer, sprintf(buffer, "\t CASE 5, HallState:  %u\r\n", HallState_Internal), 100);
//					  HAL_UART_Transmit(&huart1, (uint8_t*)buffer, sprintf(buffer, "\t CASE 2, HallCounter:  %u\r\n", HallStateCounter_Internal), 100);
//					  HAL_UART_Transmit(&huart1, (uint8_t*)buffer, sprintf(buffer, "\t CASE 5, HallStateCounter_Home:  %u\r\n", HallStateCounter_Home), 100);
//				      for(int i =0; i<5000;i++);
					break;
				default:
					HAL_UART_Transmit(&huart1, (uint8_t*)buffer, sprintf(buffer, "\t Error, HallState:  %u\r\n", HallState_Internal), 100);
//					HAL_UART_Transmit(&huart1, (uint8_t*)buffer, sprintf(buffer, "\t Error, HallCounter:  %u\r\n", HallStateCounter_Internal), 100);
//					HAL_UART_Transmit(&huart1, (uint8_t*)buffer, sprintf(buffer, "\t CASE 5, HallStateCounter_Home:  %u\r\n", HallStateCounter_Home), 100);
//					for(int i =0; i<5000;i++);
					break;
		}

		HallStateCounter_Internal = HallStateCounter_Internal%72;
		if(HallState_Internal ==7)
		{
			HallState_Internal =1;
		}

	}
	  __HAL_TIM_SET_COMPARE(&htim1,TIM_CHANNEL_1,0);
	  __HAL_TIM_SET_COMPARE(&htim1,TIM_CHANNEL_2,0);
	  __HAL_TIM_SET_COMPARE(&htim1,TIM_CHANNEL_3,0);
	  HALL_M1.HallStateCounter = HALL_M1.HallCounterHomePosition;
	  HALL_M1.HallStateHomePosition = HALL_M1.HallState;
}

void Home_Null_Offset(){
//	Null_Offset = 0;
	Null_Offset = Null_Offset + HALL_M1.HallStateCounter;
}

/**
  * @brief System Clock Configuration
  * @retval None
  */
void SystemClock_Config(void)
{
  RCC_OscInitTypeDef RCC_OscInitStruct = {0};
  RCC_ClkInitTypeDef RCC_ClkInitStruct = {0};
  RCC_PeriphCLKInitTypeDef PeriphClkInit = {0};

  /** Initializes the RCC Oscillators according to the specified parameters
  * in the RCC_OscInitTypeDef structure.
  */
  RCC_OscInitStruct.OscillatorType = RCC_OSCILLATORTYPE_HSI|RCC_OSCILLATORTYPE_HSI14;
  RCC_OscInitStruct.HSIState = RCC_HSI_ON;
  RCC_OscInitStruct.HSI14State = RCC_HSI14_ON;
  RCC_OscInitStruct.HSICalibrationValue = RCC_HSICALIBRATION_DEFAULT;
  RCC_OscInitStruct.HSI14CalibrationValue = 16;
  RCC_OscInitStruct.PLL.PLLState = RCC_PLL_ON;
  RCC_OscInitStruct.PLL.PLLSource = RCC_PLLSOURCE_HSI;
  RCC_OscInitStruct.PLL.PLLMUL = RCC_PLL_MUL12;
  RCC_OscInitStruct.PLL.PREDIV = RCC_PREDIV_DIV1;
  if (HAL_RCC_OscConfig(&RCC_OscInitStruct) != HAL_OK)
  {
    Error_Handler();
  }

  /** Initializes the CPU, AHB and APB buses clocks
  */
  RCC_ClkInitStruct.ClockType = RCC_CLOCKTYPE_HCLK|RCC_CLOCKTYPE_SYSCLK
                              |RCC_CLOCKTYPE_PCLK1;
  RCC_ClkInitStruct.SYSCLKSource = RCC_SYSCLKSOURCE_PLLCLK;
  RCC_ClkInitStruct.AHBCLKDivider = RCC_SYSCLK_DIV1;
  RCC_ClkInitStruct.APB1CLKDivider = RCC_HCLK_DIV1;

  if (HAL_RCC_ClockConfig(&RCC_ClkInitStruct, FLASH_LATENCY_1) != HAL_OK)
  {
    Error_Handler();
  }
  PeriphClkInit.PeriphClockSelection = RCC_PERIPHCLK_USART1;
  PeriphClkInit.Usart1ClockSelection = RCC_USART1CLKSOURCE_PCLK1;
  if (HAL_RCCEx_PeriphCLKConfig(&PeriphClkInit) != HAL_OK)
  {
    Error_Handler();
  }

  /** Enables the Clock Security System
  */
  HAL_RCC_EnableCSS();
}

/**
  * @brief NVIC Configuration.
  * @retval None
  */
static void MX_NVIC_Init(void)
{
  /* TIM1_BRK_UP_TRG_COM_IRQn interrupt configuration */
  HAL_NVIC_SetPriority(TIM1_BRK_UP_TRG_COM_IRQn, 0, 0);
  HAL_NVIC_EnableIRQ(TIM1_BRK_UP_TRG_COM_IRQn);
  /* DMA1_Channel1_IRQn interrupt configuration */
  HAL_NVIC_SetPriority(DMA1_Channel1_IRQn, 1, 0);
  HAL_NVIC_EnableIRQ(DMA1_Channel1_IRQn);
  /* TIM2_IRQn interrupt configuration */
  HAL_NVIC_SetPriority(TIM2_IRQn, 3, 0);
  HAL_NVIC_EnableIRQ(TIM2_IRQn);
  /* USART1_IRQn interrupt configuration */
  HAL_NVIC_SetPriority(USART1_IRQn, 3, 0);
  HAL_NVIC_EnableIRQ(USART1_IRQn);
  /* EXTI0_1_IRQn interrupt configuration */
  HAL_NVIC_SetPriority(EXTI0_1_IRQn, 3, 0);
  HAL_NVIC_EnableIRQ(EXTI0_1_IRQn);
}

/**
  * @brief ADC Initialization Function
  * @param None
  * @retval None
  */
static void MX_ADC_Init(void)
{

  /* USER CODE BEGIN ADC_Init 0 */

  /* USER CODE END ADC_Init 0 */

  ADC_ChannelConfTypeDef sConfig = {0};

  /* USER CODE BEGIN ADC_Init 1 */

  /* USER CODE END ADC_Init 1 */

  /** Configure the global features of the ADC (Clock, Resolution, Data Alignment and number of conversion)
  */
  hadc.Instance = ADC1;
  hadc.Init.ClockPrescaler = ADC_CLOCK_ASYNC_DIV1;
  hadc.Init.Resolution = ADC_RESOLUTION_12B;
  hadc.Init.DataAlign = ADC_DATAALIGN_LEFT;
  hadc.Init.ScanConvMode = ADC_SCAN_DIRECTION_FORWARD;
  hadc.Init.EOCSelection = ADC_EOC_SINGLE_CONV;
  hadc.Init.LowPowerAutoWait = DISABLE;
  hadc.Init.LowPowerAutoPowerOff = DISABLE;
  hadc.Init.ContinuousConvMode = DISABLE;
  hadc.Init.DiscontinuousConvMode = DISABLE;
  hadc.Init.ExternalTrigConv = ADC_EXTERNALTRIGCONV_T1_TRGO;
  hadc.Init.ExternalTrigConvEdge = ADC_EXTERNALTRIGCONVEDGE_RISING;
  hadc.Init.DMAContinuousRequests = ENABLE;
  hadc.Init.Overrun = ADC_OVR_DATA_PRESERVED;
  if (HAL_ADC_Init(&hadc) != HAL_OK)
  {
    Error_Handler();
  }

  /** Configure for the selected ADC regular channel to be converted.
  */
  sConfig.Channel = ADC_CHANNEL_3;
  sConfig.Rank = ADC_RANK_CHANNEL_NUMBER;
  sConfig.SamplingTime = ADC_SAMPLETIME_7CYCLES_5;
  if (HAL_ADC_ConfigChannel(&hadc, &sConfig) != HAL_OK)
  {
    Error_Handler();
  }

  /** Configure for the selected ADC regular channel to be converted.
  */
  sConfig.Channel = ADC_CHANNEL_4;
  if (HAL_ADC_ConfigChannel(&hadc, &sConfig) != HAL_OK)
  {
    Error_Handler();
  }

  /** Configure for the selected ADC regular channel to be converted.
  */
  sConfig.Channel = ADC_CHANNEL_5;
  if (HAL_ADC_ConfigChannel(&hadc, &sConfig) != HAL_OK)
  {
    Error_Handler();
  }

  /** Configure for the selected ADC regular channel to be converted.
  */
  sConfig.Channel = ADC_CHANNEL_9;
  if (HAL_ADC_ConfigChannel(&hadc, &sConfig) != HAL_OK)
  {
    Error_Handler();
  }
  /* USER CODE BEGIN ADC_Init 2 */

  /* USER CODE END ADC_Init 2 */

}

/**
  * @brief TIM1 Initialization Function
  * @param None
  * @retval None
  */
static void MX_TIM1_Init(void)
{

  /* USER CODE BEGIN TIM1_Init 0 */

  /* USER CODE END TIM1_Init 0 */

  TIM_MasterConfigTypeDef sMasterConfig = {0};
  TIM_OC_InitTypeDef sConfigOC = {0};
  TIM_BreakDeadTimeConfigTypeDef sBreakDeadTimeConfig = {0};

  /* USER CODE BEGIN TIM1_Init 1 */

  /* USER CODE END TIM1_Init 1 */
  htim1.Instance = TIM1;
  htim1.Init.Prescaler = ((TIM_CLOCK_DIVIDER) - 1);
  htim1.Init.CounterMode = TIM_COUNTERMODE_CENTERALIGNED1;
  htim1.Init.Period = ((PWM_PERIOD_CYCLES) / 2);
  htim1.Init.ClockDivision = TIM_CLOCKDIVISION_DIV2;
  htim1.Init.RepetitionCounter = (REP_COUNTER);
  htim1.Init.AutoReloadPreload = TIM_AUTORELOAD_PRELOAD_DISABLE;
  if (HAL_TIM_PWM_Init(&htim1) != HAL_OK)
  {
    Error_Handler();
  }
  sMasterConfig.MasterOutputTrigger = TIM_TRGO_OC4REF;
  sMasterConfig.MasterSlaveMode = TIM_MASTERSLAVEMODE_DISABLE;
  if (HAL_TIMEx_MasterConfigSynchronization(&htim1, &sMasterConfig) != HAL_OK)
  {
    Error_Handler();
  }
  sConfigOC.OCMode = TIM_OCMODE_PWM1;
  sConfigOC.Pulse = 0;
  sConfigOC.OCPolarity = TIM_OCPOLARITY_HIGH;
  sConfigOC.OCNPolarity = TIM_OCNPOLARITY_HIGH;
  sConfigOC.OCFastMode = TIM_OCFAST_DISABLE;
  sConfigOC.OCIdleState = TIM_OCIDLESTATE_RESET;
  sConfigOC.OCNIdleState = TIM_OCNIDLESTATE_RESET;
  if (HAL_TIM_PWM_ConfigChannel(&htim1, &sConfigOC, TIM_CHANNEL_1) != HAL_OK)
  {
    Error_Handler();
  }
  if (HAL_TIM_PWM_ConfigChannel(&htim1, &sConfigOC, TIM_CHANNEL_2) != HAL_OK)
  {
    Error_Handler();
  }
  if (HAL_TIM_PWM_ConfigChannel(&htim1, &sConfigOC, TIM_CHANNEL_3) != HAL_OK)
  {
    Error_Handler();
  }
  sConfigOC.OCMode = TIM_OCMODE_PWM2;
  sConfigOC.Pulse = (((PWM_PERIOD_CYCLES) / 2) - (HTMIN));
  if (HAL_TIM_PWM_ConfigChannel(&htim1, &sConfigOC, TIM_CHANNEL_4) != HAL_OK)
  {
    Error_Handler();
  }
  sBreakDeadTimeConfig.OffStateRunMode = TIM_OSSR_ENABLE;
  sBreakDeadTimeConfig.OffStateIDLEMode = TIM_OSSI_ENABLE;
  sBreakDeadTimeConfig.LockLevel = TIM_LOCKLEVEL_1;
  sBreakDeadTimeConfig.DeadTime = ((DEAD_TIME_COUNTS) / 2);
  sBreakDeadTimeConfig.BreakState = TIM_BREAK_ENABLE;
  sBreakDeadTimeConfig.BreakPolarity = TIM_BREAKPOLARITY_HIGH;
  sBreakDeadTimeConfig.AutomaticOutput = TIM_AUTOMATICOUTPUT_DISABLE;
  if (HAL_TIMEx_ConfigBreakDeadTime(&htim1, &sBreakDeadTimeConfig) != HAL_OK)
  {
    Error_Handler();
  }
  /* USER CODE BEGIN TIM1_Init 2 */

  /* USER CODE END TIM1_Init 2 */
  HAL_TIM_MspPostInit(&htim1);

}

/**
  * @brief TIM2 Initialization Function
  * @param None
  * @retval None
  */
static void MX_TIM2_Init(void)
{

  /* USER CODE BEGIN TIM2_Init 0 */

  /* USER CODE END TIM2_Init 0 */

  TIM_ClockConfigTypeDef sClockSourceConfig = {0};
  TIM_HallSensor_InitTypeDef sConfig = {0};
  TIM_MasterConfigTypeDef sMasterConfig = {0};

  /* USER CODE BEGIN TIM2_Init 1 */

  /* USER CODE END TIM2_Init 1 */
  htim2.Instance = TIM2;
  htim2.Init.Prescaler = 0;
  htim2.Init.CounterMode = TIM_COUNTERMODE_UP;
  htim2.Init.Period = M1_HALL_TIM_PERIOD;
  htim2.Init.ClockDivision = TIM_CLOCKDIVISION_DIV1;
  htim2.Init.AutoReloadPreload = TIM_AUTORELOAD_PRELOAD_DISABLE;
  if (HAL_TIM_Base_Init(&htim2) != HAL_OK)
  {
    Error_Handler();
  }
  sClockSourceConfig.ClockSource = TIM_CLOCKSOURCE_INTERNAL;
  if (HAL_TIM_ConfigClockSource(&htim2, &sClockSourceConfig) != HAL_OK)
  {
    Error_Handler();
  }
  sConfig.IC1Polarity = TIM_ICPOLARITY_RISING;
  sConfig.IC1Prescaler = TIM_ICPSC_DIV1;
  sConfig.IC1Filter = M1_HALL_IC_FILTER;
  sConfig.Commutation_Delay = 0;
  if (HAL_TIMEx_HallSensor_Init(&htim2, &sConfig) != HAL_OK)
  {
    Error_Handler();
  }
  sMasterConfig.MasterOutputTrigger = TIM_TRGO_OC2REF;
  sMasterConfig.MasterSlaveMode = TIM_MASTERSLAVEMODE_DISABLE;
  if (HAL_TIMEx_MasterConfigSynchronization(&htim2, &sMasterConfig) != HAL_OK)
  {
    Error_Handler();
  }
  /* USER CODE BEGIN TIM2_Init 2 */

  /* USER CODE END TIM2_Init 2 */

}

/**
  * @brief TIM14 Initialization Function
  * @param None
  * @retval None
  */
static void MX_TIM14_Init(void)
{

  /* USER CODE BEGIN TIM14_Init 0 */

  /* USER CODE END TIM14_Init 0 */

  TIM_OC_InitTypeDef sConfigOC = {0};

  /* USER CODE BEGIN TIM14_Init 1 */

  /* USER CODE END TIM14_Init 1 */
  htim14.Instance = TIM14;
  htim14.Init.Prescaler = 0;
  htim14.Init.CounterMode = TIM_COUNTERMODE_UP;
  htim14.Init.Period = 0x800;
  htim14.Init.ClockDivision = TIM_CLOCKDIVISION_DIV1;
  htim14.Init.AutoReloadPreload = TIM_AUTORELOAD_PRELOAD_DISABLE;
  if (HAL_TIM_Base_Init(&htim14) != HAL_OK)
  {
    Error_Handler();
  }
  if (HAL_TIM_PWM_Init(&htim14) != HAL_OK)
  {
    Error_Handler();
  }
  sConfigOC.OCMode = TIM_OCMODE_PWM1;
  sConfigOC.Pulse = 0x400;
  sConfigOC.OCPolarity = TIM_OCPOLARITY_HIGH;
  sConfigOC.OCFastMode = TIM_OCFAST_DISABLE;
  if (HAL_TIM_PWM_ConfigChannel(&htim14, &sConfigOC, TIM_CHANNEL_1) != HAL_OK)
  {
    Error_Handler();
  }
  /* USER CODE BEGIN TIM14_Init 2 */

  /* USER CODE END TIM14_Init 2 */
  HAL_TIM_MspPostInit(&htim14);

}

/**
  * @brief USART1 Initialization Function
  * @param None
  * @retval None
  */
static void MX_USART1_UART_Init(void)
{

  /* USER CODE BEGIN USART1_Init 0 */

  /* USER CODE END USART1_Init 0 */

  /* USER CODE BEGIN USART1_Init 1 */

  /* USER CODE END USART1_Init 1 */
  huart1.Instance = USART1;
  huart1.Init.BaudRate = 9600;
  huart1.Init.WordLength = UART_WORDLENGTH_8B;
  huart1.Init.StopBits = UART_STOPBITS_1;
  huart1.Init.Parity = UART_PARITY_NONE;
  huart1.Init.Mode = UART_MODE_TX_RX;
  huart1.Init.HwFlowCtl = UART_HWCONTROL_NONE;
  huart1.Init.OverSampling = UART_OVERSAMPLING_16;
  huart1.Init.OneBitSampling = UART_ONE_BIT_SAMPLE_DISABLE;
  huart1.AdvancedInit.AdvFeatureInit = UART_ADVFEATURE_NO_INIT;
  if (HAL_UART_Init(&huart1) != HAL_OK)
  {
    Error_Handler();
  }
  /* USER CODE BEGIN USART1_Init 2 */

  /* USER CODE END USART1_Init 2 */

}

/**
  * Enable DMA controller clock
  */
static void MX_DMA_Init(void)
{

  /* DMA controller clock enable */
  __HAL_RCC_DMA1_CLK_ENABLE();

}

/**
  * @brief GPIO Initialization Function
  * @param None
  * @retval None
  */
static void MX_GPIO_Init(void)
{
  GPIO_InitTypeDef GPIO_InitStruct = {0};

  /* GPIO Ports Clock Enable */
  __HAL_RCC_GPIOF_CLK_ENABLE();
  __HAL_RCC_GPIOA_CLK_ENABLE();
  __HAL_RCC_GPIOB_CLK_ENABLE();

  /*Configure GPIO pin Output Level */
  HAL_GPIO_WritePin(OC_SEL_GPIO_Port, OC_SEL_Pin, GPIO_PIN_SET);

  /*Configure GPIO pin Output Level */
  HAL_GPIO_WritePin(_3FG_HIZ_GPIO_Port, _3FG_HIZ_Pin, GPIO_PIN_RESET);

  /*Configure GPIO pin Output Level */
  HAL_GPIO_WritePin(OCTH_STBY2_GPIO_Port, OCTH_STBY2_Pin, GPIO_PIN_RESET);

  /*Configure GPIO pin Output Level */
  HAL_GPIO_WritePin(OCTH_STBY1_GPIO_Port, OCTH_STBY1_Pin, GPIO_PIN_SET);

  /*Configure GPIO pin : Start_Stop_Pin */
  GPIO_InitStruct.Pin = Start_Stop_Pin;
  GPIO_InitStruct.Mode = GPIO_MODE_IT_FALLING;
  GPIO_InitStruct.Pull = GPIO_PULLUP;
  HAL_GPIO_Init(Start_Stop_GPIO_Port, &GPIO_InitStruct);

  /*Configure GPIO pins : OC_SEL_Pin _3FG_HIZ_Pin */
  GPIO_InitStruct.Pin = OC_SEL_Pin|_3FG_HIZ_Pin;
  GPIO_InitStruct.Mode = GPIO_MODE_OUTPUT_PP;
  GPIO_InitStruct.Pull = GPIO_PULLDOWN;
  GPIO_InitStruct.Speed = GPIO_SPEED_FREQ_LOW;
  HAL_GPIO_Init(GPIOA, &GPIO_InitStruct);

  /*Configure GPIO pins : OCTH_STBY2_Pin OCTH_STBY1_Pin */
  GPIO_InitStruct.Pin = OCTH_STBY2_Pin|OCTH_STBY1_Pin;
  GPIO_InitStruct.Mode = GPIO_MODE_OUTPUT_PP;
  GPIO_InitStruct.Pull = GPIO_PULLDOWN;
  GPIO_InitStruct.Speed = GPIO_SPEED_FREQ_LOW;
  HAL_GPIO_Init(GPIOF, &GPIO_InitStruct);

}

/* USER CODE BEGIN 4 */

/* USER CODE END 4 */

/**
  * @brief  This function is executed in case of error occurrence.
  * @retval None
  */
void Error_Handler(void)
{
  /* USER CODE BEGIN Error_Handler_Debug */
  /* User can add his own implementation to report the HAL error return state */
  __disable_irq();
  while (1)
  {
  }
  /* USER CODE END Error_Handler_Debug */
}

#ifdef  USE_FULL_ASSERT
/**
  * @brief  Reports the name of the source file and the source line number
  *         where the assert_param error has occurred.
  * @param  file: pointer to the source file name
  * @param  line: assert_param error line source number
  * @retval None
  */
void assert_failed(uint8_t *file, uint32_t line)
{
  /* USER CODE BEGIN 6 */
  /* User can add his own implementation to report the file name and line number,
     ex: printf("Wrong parameters value: file %s on line %d\r\n", file, line) */
  /* USER CODE END 6 */
}
#endif /* USE_FULL_ASSERT */

void MainWhile_Homing(){
	  /*--My code--*/
	  /*--My code ends --*/
    /* USER CODE END WHILE */
//	  oldAngle =(uint16_t *) HALL_M1.HallState;

/* 	  	  if( HALL_M1.HallStateCounter != 0 && moveMotor) //Default Position 0
	  	  {

	  		  if(stepA && pendingPhase)
	  		  {
	  //			  HAL_UART_Transmit(&huart1, (uint8_t*)buffer, sprintf(buffer, "in phase control\n"), 100);
	  			  __HAL_TIM_SET_COMPARE(&htim1,TIM_CHANNEL_3,0);
	  			  __HAL_TIM_SET_COMPARE(&htim1,TIM_CHANNEL_1,pulse);
	  			    __HAL_TIM_SET_COMPARE(&htim1,TIM_CHANNEL_2,0);
	  			  stepA =0 ;
	  			  stepAB=1;
	  			  pendingPhase = 0;
	  			  execute++;
	  		  }
	  		  if(stepAB && pendingPhase)
	  		  {
	  //			  HAL_UART_Transmit(&huart1, (uint8_t*)buffer, sprintf(buffer, "in phase control\n"), 100);
	  		  	  __HAL_TIM_SET_COMPARE(&htim1,TIM_CHANNEL_3,0);
	  		  	  __HAL_TIM_SET_COMPARE(&htim1,TIM_CHANNEL_1,pulse);
	  		  	  __HAL_TIM_SET_COMPARE(&htim1,TIM_CHANNEL_2,pulse);
	  		  	   stepAB =0 ;
	  		  	   stepB=1;
	  		  	   pendingPhase = 0;
	  		  	}
	  		  if(stepB && pendingPhase)
	  		  	{
				  __HAL_TIM_SET_COMPARE(&htim1,TIM_CHANNEL_1,0);
				  __HAL_TIM_SET_COMPARE(&htim1,TIM_CHANNEL_2,pulse);
				  __HAL_TIM_SET_COMPARE(&htim1,TIM_CHANNEL_3,0);
				  stepB = 0;
				  stepBC =1;
				  pendingPhase = 0;
	  		  	}
	  		  if(stepBC && pendingPhase)
	  		  	{
	  		  	    __HAL_TIM_SET_COMPARE(&htim1,TIM_CHANNEL_1,0);
	  		  	    __HAL_TIM_SET_COMPARE(&htim1,TIM_CHANNEL_2,pulse);
	  		  	    __HAL_TIM_SET_COMPARE(&htim1,TIM_CHANNEL_3,pulse);
	  		  	    stepBC = 0;
	  		  	    stepC =1;
	  		  	    pendingPhase = 0;
	  		  	 }
	  	      if(stepC && pendingPhase)
	  	      	 {
					__HAL_TIM_SET_COMPARE(&htim1,TIM_CHANNEL_1,0);
					__HAL_TIM_SET_COMPARE(&htim1,TIM_CHANNEL_2,0);
					__HAL_TIM_SET_COMPARE(&htim1,TIM_CHANNEL_3,pulse);
					stepC = 0;
					stepCA=1;
					pendingPhase = 0;
	  	         }
	  	      if(stepCA && pendingPhase)
	  	      	 {
					 __HAL_TIM_SET_COMPARE(&htim1,TIM_CHANNEL_1,pulse);
					 __HAL_TIM_SET_COMPARE(&htim1,TIM_CHANNEL_2,0);
					 __HAL_TIM_SET_COMPARE(&htim1,TIM_CHANNEL_3,pulse);
					stepC = 0;
					stepA=1;
					pendingPhase = 0;
	  	      	  }

	  	        pendingPhase = 1;

	  	  }
	  	  else
	  	  {
				  __HAL_TIM_SET_COMPARE(&htim1,TIM_CHANNEL_1,0);
				  __HAL_TIM_SET_COMPARE(&htim1,TIM_CHANNEL_2,0);
				  __HAL_TIM_SET_COMPARE(&htim1,TIM_CHANNEL_3,0);
				  moveMotor = 0;
				  if(count == 0 )
				  {
						   oldhallstate =(uint16_t *) HALL_M1.HallState;
						   count =1;
				  }
					  execute=0;
					  HAL_Delay(0.1);

	  	  }

	  	  presenthallstate = (uint16_t *) HALL_M1.HallState;

		  if( HALL_M1.HallState == 71 && (oldhallstate != presenthallstate))
					  {
						  if( oldhallstate < presenthallstate)
						  {
							  HALL_M1.HallStateCounter = HALL_M1.HallStateCounter-oldhallstate+1;
							 // execute = execute - oldhallstate;
						  }
						  else
						  {
							  HALL_M1.HallStateCounter = HALL_M1.HallStateCounter-presenthallstate-1;
							 // execute = execute - presenthallstate;
						  }

						 count =0;
						 execute=0;
					  }
		  HAL_UART_Transmit(&huart1, (uint8_t*)buffer, sprintf(buffer, "\n at pole: %u\r\n", HALL_M1.HallStateCounter), 75);

		  execute = execute%7;
		 // HAL_Delay(10);
		  waitToMoveCounter++;
		  if(moveMotor == 0 && waitToMoveCounter >=50)
		  {
			  moveMotor =1;
			  waitToMoveCounter=0;
		  }*/
}
void OSC_MODE_HOME2(){

	  if( HALL_M1.HallStateCounter != 0 && moveMotor) //Default Position 0
  	  {

  		  if(stepA && pendingPhase)
  		  {
  //			  HAL_UART_Transmit(&huart1, (uint8_t*)buffer, sprintf(buffer, "in phase control\n"), 100);
  			  __HAL_TIM_SET_COMPARE(&htim1,TIM_CHANNEL_3,0);
  			  __HAL_TIM_SET_COMPARE(&htim1,TIM_CHANNEL_1,pulse);
  			    __HAL_TIM_SET_COMPARE(&htim1,TIM_CHANNEL_2,0);
  			  stepA =0 ;
  			  stepAB=1;
  			  pendingPhase = 0;
  			  execute++;
  		  }
  		  if(stepAB && pendingPhase)
  		  {
  //			  HAL_UART_Transmit(&huart1, (uint8_t*)buffer, sprintf(buffer, "in phase control\n"), 100);
  		  	  __HAL_TIM_SET_COMPARE(&htim1,TIM_CHANNEL_3,0);
  		  	  __HAL_TIM_SET_COMPARE(&htim1,TIM_CHANNEL_1,pulse);
  		  	  __HAL_TIM_SET_COMPARE(&htim1,TIM_CHANNEL_2,pulse);
  		  	   stepAB =0 ;
  		  	   stepB=1;
  		  	   pendingPhase = 0;
  		  	}
  		  if(stepB && pendingPhase)
  		  	{
			  __HAL_TIM_SET_COMPARE(&htim1,TIM_CHANNEL_1,0);
			  __HAL_TIM_SET_COMPARE(&htim1,TIM_CHANNEL_2,pulse);
			  __HAL_TIM_SET_COMPARE(&htim1,TIM_CHANNEL_3,0);
			  stepB = 0;
			  stepBC =1;
			  pendingPhase = 0;
  		  	}
  		  if(stepBC && pendingPhase)
  		  	{
  		  	    __HAL_TIM_SET_COMPARE(&htim1,TIM_CHANNEL_1,0);
  		  	    __HAL_TIM_SET_COMPARE(&htim1,TIM_CHANNEL_2,pulse);
  		  	    __HAL_TIM_SET_COMPARE(&htim1,TIM_CHANNEL_3,pulse);
  		  	    stepBC = 0;
  		  	    stepC =1;
  		  	    pendingPhase = 0;
  		  	 }
  	      if(stepC && pendingPhase)
  	      	 {
				__HAL_TIM_SET_COMPARE(&htim1,TIM_CHANNEL_1,0);
				__HAL_TIM_SET_COMPARE(&htim1,TIM_CHANNEL_2,0);
				__HAL_TIM_SET_COMPARE(&htim1,TIM_CHANNEL_3,pulse);
				stepC = 0;
				stepCA=1;
				pendingPhase = 0;
  	         }
  	      if(stepCA && pendingPhase)
  	      	 {
				 __HAL_TIM_SET_COMPARE(&htim1,TIM_CHANNEL_1,pulse);
				 __HAL_TIM_SET_COMPARE(&htim1,TIM_CHANNEL_2,0);
				 __HAL_TIM_SET_COMPARE(&htim1,TIM_CHANNEL_3,pulse);
				stepC = 0;
				stepA=1;
				pendingPhase = 0;
  	      	  }

  	        pendingPhase = 1;

  	  }
  	  else
  	  {
			  __HAL_TIM_SET_COMPARE(&htim1,TIM_CHANNEL_1,0);
			  __HAL_TIM_SET_COMPARE(&htim1,TIM_CHANNEL_2,0);
			  __HAL_TIM_SET_COMPARE(&htim1,TIM_CHANNEL_3,0);
			  moveMotor = 0;
			  if(count == 0 )
			  {
					//   oldhallstate =(uint16_t *) HALL_M1.HallState;
					   count =1;
			  }
				  execute=0;
				  HAL_Delay(0.1);

  	  }

  	 // presenthallstate = (uint16_t *) HALL_M1.HallState;

	  if( HALL_M1.HallState == 71 && (HALL_M1.HallStateHomePosition != HALL_M1.HallState))
				  {
					  if( oldhallstate < HALL_M1.HallState)
					  {
						  HALL_M1.HallStateCounter = HALL_M1.HallStateCounter-HALL_M1.HallStateHomePosition+1;
						 // execute = execute - oldhallstate;
					  }
					  else
					  {
						  HALL_M1.HallStateCounter = HALL_M1.HallStateCounter-HALL_M1.HallState-1;
						 // execute = execute - presenthallstate;
					  }

					 count =0;
					 execute=0;
				  }
	  HAL_UART_Transmit(&huart1, (uint8_t*)buffer, sprintf(buffer, "\n at pole: %u\r\n", HALL_M1.HallStateCounter), 75);

	  execute = execute%7;
	 // HAL_Delay(10);
	  waitToMoveCounter++;
	  if(moveMotor == 0 && waitToMoveCounter >=50)
	  {
		  moveMotor =1;
		  waitToMoveCounter=0;
	  }
}

/*-- My code --*/
void OSC_MODE_HOME(){

//	while(HALL_M1.HallStateCounter != 0){
//		 HAL_UART_Transmit(&huart1, (uint8_t*)buffer, sprintf(buffer, "\t HOMING COunter: %u\r\n", HALL_M1.HallStateCounter), 100);
//	moveMotor = 1;
	int diff = HALL_M1.HallStateCounter - HALL_M1.HallStateHomePosition;
	for(int i = 0; i<=diff;){
//			 HAL_UART_Transmit(&huart1, (uint8_t*)buffer, sprintf(buffer, "\t DO COunter: %u\r\n", HALL_M1.HallStateCounter), 100);
//			 HAL_UART_Transmit(&huart1, (uint8_t*)buffer, sprintf(buffer, "\t DO hallPosition: %u\r\n", HALL_M1.HallState), 100);
			 //HAL_Delay(1000);
//while(HALL_M1.HallStateCounter != HALL_M1.HallCounterHomePosition){
	if( HALL_M1.HallStateCounter != HALL_M1.HallCounterHomePosition && moveMotor) //Default Position 0
	  	  {
			 HAL_UART_Transmit(&huart1, (uint8_t*)buffer, sprintf(buffer, "\t MOVING COunter: %u\r\n", HALL_M1.HallStateCounter), 100);
			 HAL_UART_Transmit(&huart1, (uint8_t*)buffer, sprintf(buffer, "\t MOVING hallposition: %u\r\n", HALL_M1.HallState), 100);
			// HAL_Delay(1000);
	  		  if(stepA && pendingPhase)
	  		  {
	  //			  HAL_UART_Transmit(&huart1, (uint8_t*)buffer, sprintf(buffer, "in phase control\n"), 100);
	  			  __HAL_TIM_SET_COMPARE(&htim1,TIM_CHANNEL_3,0);
	  			  __HAL_TIM_SET_COMPARE(&htim1,TIM_CHANNEL_1,pulse);
	  			    __HAL_TIM_SET_COMPARE(&htim1,TIM_CHANNEL_2,0);
	  			  stepA =0 ;
	  			  stepAB=1;
	  			  pendingPhase = 0;
	  			  execute++;
	  			  i++;
	  		  }
	  		  if(stepAB && pendingPhase)
	  		  {
	  //			  HAL_UART_Transmit(&huart1, (uint8_t*)buffer, sprintf(buffer, "in phase control\n"), 100);
	  		  	  __HAL_TIM_SET_COMPARE(&htim1,TIM_CHANNEL_3,0);
	  		  	  __HAL_TIM_SET_COMPARE(&htim1,TIM_CHANNEL_1,pulse);
	  		  	  __HAL_TIM_SET_COMPARE(&htim1,TIM_CHANNEL_2,pulse);
	  		  	   stepAB =0 ;
	  		  	   stepB=1;
	  		  	   pendingPhase = 0;
	  		  	}
	  		  if(stepB && pendingPhase)
	  		  	{
				  __HAL_TIM_SET_COMPARE(&htim1,TIM_CHANNEL_1,0);
				  __HAL_TIM_SET_COMPARE(&htim1,TIM_CHANNEL_2,pulse);
				  __HAL_TIM_SET_COMPARE(&htim1,TIM_CHANNEL_3,0);
				  stepB = 0;
				  stepBC =1;
				  pendingPhase = 0;
	  		  	}
	  		  if(stepBC && pendingPhase)
	  		  	{
	  		  	    __HAL_TIM_SET_COMPARE(&htim1,TIM_CHANNEL_1,0);
	  		  	    __HAL_TIM_SET_COMPARE(&htim1,TIM_CHANNEL_2,pulse);
	  		  	    __HAL_TIM_SET_COMPARE(&htim1,TIM_CHANNEL_3,pulse);
	  		  	    stepBC = 0;
	  		  	    stepC =1;
	  		  	    pendingPhase = 0;
	  		  	 }
	  	      if(stepC && pendingPhase)
	  	      	 {
					__HAL_TIM_SET_COMPARE(&htim1,TIM_CHANNEL_1,0);
					__HAL_TIM_SET_COMPARE(&htim1,TIM_CHANNEL_2,0);
					__HAL_TIM_SET_COMPARE(&htim1,TIM_CHANNEL_3,pulse);
					stepC = 0;
					stepCA=1;
					pendingPhase = 0;
	  	         }
	  	      if(stepCA && pendingPhase)
	  	      	 {
					 __HAL_TIM_SET_COMPARE(&htim1,TIM_CHANNEL_1,pulse);
					 __HAL_TIM_SET_COMPARE(&htim1,TIM_CHANNEL_2,0);
					 __HAL_TIM_SET_COMPARE(&htim1,TIM_CHANNEL_3,pulse);
					stepC = 0;
					stepA=1;
					pendingPhase = 0;
	  	      	  }

	  	        pendingPhase = 1;

	  	  }
	  	  else
	  	  {
				  __HAL_TIM_SET_COMPARE(&htim1,TIM_CHANNEL_1,0);
				  __HAL_TIM_SET_COMPARE(&htim1,TIM_CHANNEL_2,0);
				  __HAL_TIM_SET_COMPARE(&htim1,TIM_CHANNEL_3,0);
				  moveMotor = 0;
				  if(count == 0 )
				  {
						   oldhallstate =(uint16_t *) HALL_M1.HallState;
						   count =1;
				  }
					  execute=0;
					  HAL_Delay(0.1);

	  	  }

	  	 // presenthallstate = (uint16_t *) HALL_M1.HallState;

		  if( HALL_M1.HallState == 71 && (HALL_M1.HallStateHomePosition != HALL_M1.HallState))
					  {
						  if( HALL_M1.HallStateHomePosition < HALL_M1.HallState)
						  {
							  HALL_M1.HallStateCounter = HALL_M1.HallStateCounter-HALL_M1.HallState+1;
							 // execute = execute - oldhallstate;
						  }
						  else
						  {
							  HALL_M1.HallStateCounter = HALL_M1.HallStateCounter-HALL_M1.HallState-1;
							 // execute = execute - presenthallstate;
						  }

						 count =0;
						 execute=0;
					  }
//		  HAL_UART_Transmit(&huart1, (uint8_t*)buffer, sprintf(buffer, "\n at pole: %u\r\n", HALL_M1.HallStateCounter), 75);

		  execute = execute%7;
		 // HAL_Delay(10);
		  waitToMoveCounter++;
		  if(moveMotor == 0 && waitToMoveCounter >=50)
		  {
			  moveMotor =1;
			  waitToMoveCounter=0;
		  }
}
}//while(HALL_M1.HallStateCounter != 0);
//}
/*-- My code ends --*/
